AUTOSAR XML (schema 00050)
package /STLASWCs
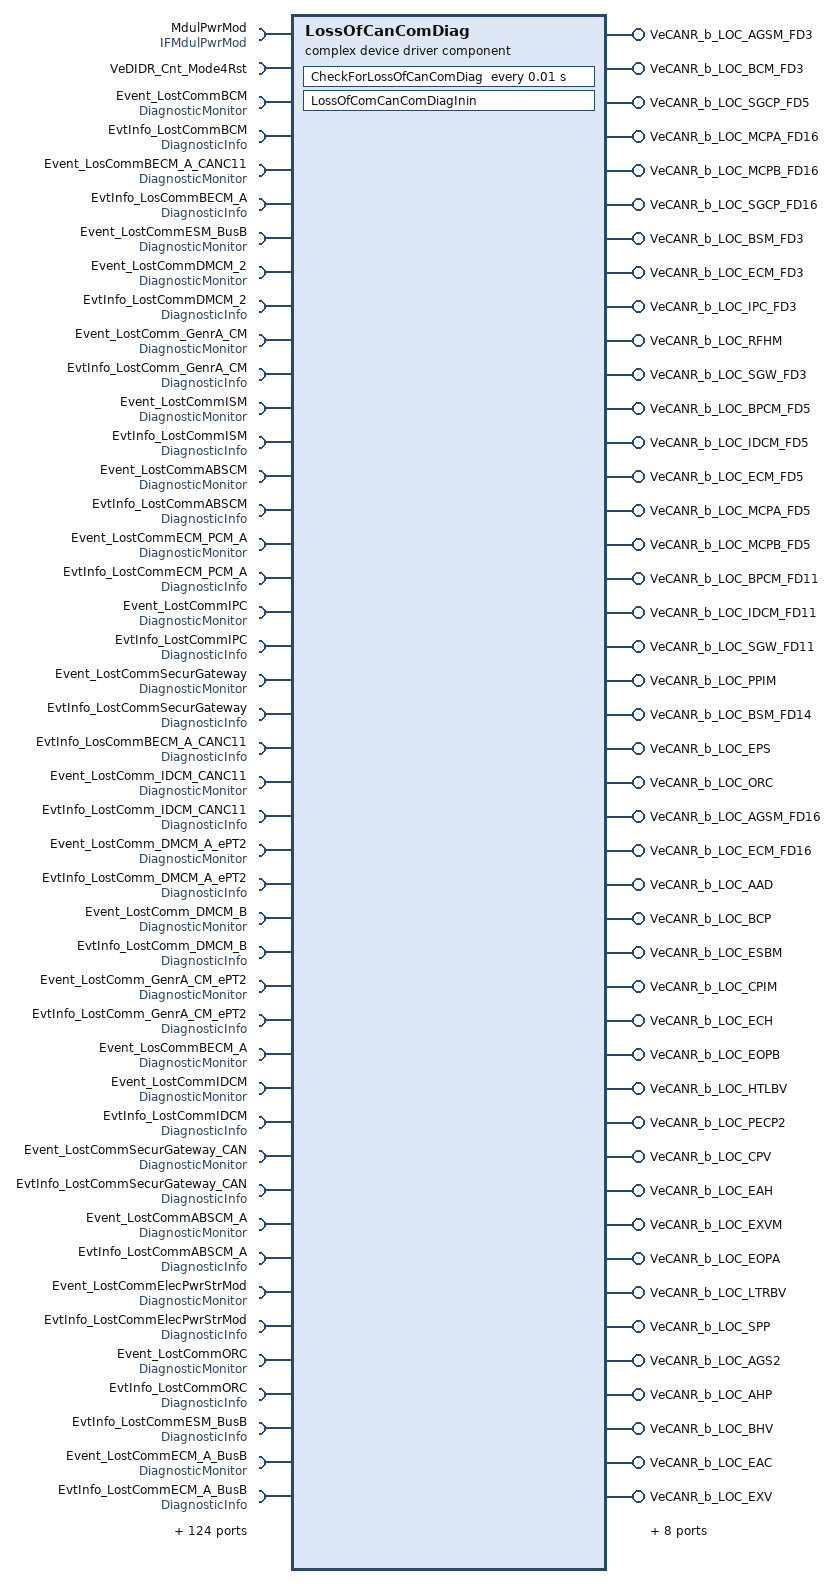
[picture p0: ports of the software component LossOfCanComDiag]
  complex device driver sw component type LossOfCanComDiag  # Loss Of CAN Communication Diagnosis | Loss of CAN Communication Diagnosis Component - implements Loss of Communications (LOC) detection on the CAN bus.
    46 x require port:
      MdulPwrMod: mode-switch-receiver-com-spec=AppMode_MDGP_ESH_Mode, required-interface=IFMdulPwrMod
      VeDIDR_Cnt_Mode4Rst: nonqueued-receiver-com-spec{data-element=VeDIDR_Cnt_Mode4Rst, init-value=0}, required-interface=VeDIDR_Cnt_Mode4Rst
      Event_LostCommBCM: client-com-spec=SetEventStatus, required-interface=DiagnosticMonitor
      EvtInfo_LostCommBCM: client-com-spec=GetEventStatus, required-interface=DiagnosticInfo
      Event_LosCommBECM_A_CANC11: client-com-spec=SetEventStatus, required-interface=DiagnosticMonitor
      EvtInfo_LosCommBECM_A: client-com-spec=GetEventStatus, required-interface=DiagnosticInfo
      Event_LostCommESM_BusB: client-com-spec=SetEventStatus, required-interface=DiagnosticMonitor
      Event_LostCommDMCM_2: client-com-spec=SetEventStatus, required-interface=DiagnosticMonitor
      EvtInfo_LostCommDMCM_2: client-com-spec=GetEventStatus, required-interface=DiagnosticInfo
      Event_LostComm_GenrA_CM: client-com-spec=SetEventStatus, required-interface=DiagnosticMonitor
      EvtInfo_LostComm_GenrA_CM: client-com-spec=GetEventStatus, required-interface=DiagnosticInfo
      Event_LostCommISM: client-com-spec=SetEventStatus, required-interface=DiagnosticMonitor
      EvtInfo_LostCommISM: client-com-spec=GetEventStatus, required-interface=DiagnosticInfo
      Event_LostCommABSCM: client-com-spec=SetEventStatus, required-interface=DiagnosticMonitor
      EvtInfo_LostCommABSCM: client-com-spec=GetEventStatus, required-interface=DiagnosticInfo
      Event_LostCommECM_PCM_A: client-com-spec=SetEventStatus, required-interface=DiagnosticMonitor
      EvtInfo_LostCommECM_PCM_A: client-com-spec=GetEventStatus, required-interface=DiagnosticInfo
      Event_LostCommIPC: client-com-spec=SetEventStatus, required-interface=DiagnosticMonitor
      EvtInfo_LostCommIPC: client-com-spec=GetEventStatus, required-interface=DiagnosticInfo
      Event_LostCommSecurGateway: client-com-spec=SetEventStatus, required-interface=DiagnosticMonitor
      EvtInfo_LostCommSecurGateway: client-com-spec=GetEventStatus, required-interface=DiagnosticInfo
      EvtInfo_LosCommBECM_A_CANC11: client-com-spec=GetEventStatus, required-interface=DiagnosticInfo
      Event_LostComm_IDCM_CANC11: client-com-spec=SetEventStatus, required-interface=DiagnosticMonitor
      EvtInfo_LostComm_IDCM_CANC11: client-com-spec=GetEventStatus, required-interface=DiagnosticInfo
      Event_LostComm_DMCM_A_ePT2: client-com-spec=SetEventStatus, required-interface=DiagnosticMonitor
      EvtInfo_LostComm_DMCM_A_ePT2: client-com-spec=GetEventStatus, required-interface=DiagnosticInfo
      Event_LostComm_DMCM_B: client-com-spec=SetEventStatus, required-interface=DiagnosticMonitor
      EvtInfo_LostComm_DMCM_B: client-com-spec=GetEventStatus, required-interface=DiagnosticInfo
      Event_LostComm_GenrA_CM_ePT2: client-com-spec=SetEventStatus, required-interface=DiagnosticMonitor
      EvtInfo_LostComm_GenrA_CM_ePT2: client-com-spec=GetEventStatus, required-interface=DiagnosticInfo
      Event_LosCommBECM_A: client-com-spec=SetEventStatus, required-interface=DiagnosticMonitor
      Event_LostCommIDCM: client-com-spec=SetEventStatus, required-interface=DiagnosticMonitor
      EvtInfo_LostCommIDCM: client-com-spec=GetEventStatus, required-interface=DiagnosticInfo
      Event_LostCommSecurGateway_CAN: client-com-spec=SetEventStatus, required-interface=DiagnosticMonitor
      EvtInfo_LostCommSecurGateway_CAN: client-com-spec=GetEventStatus, required-interface=DiagnosticInfo
      Event_LostCommABSCM_A: client-com-spec=SetEventStatus, required-interface=DiagnosticMonitor
      EvtInfo_LostCommABSCM_A: client-com-spec=GetEventStatus, required-interface=DiagnosticInfo
      Event_LostCommElecPwrStrMod: client-com-spec=SetEventStatus, required-interface=DiagnosticMonitor
      EvtInfo_LostCommElecPwrStrMod: client-com-spec=GetEventStatus, required-interface=DiagnosticInfo
      Event_LostCommORC: client-com-spec=SetEventStatus, required-interface=DiagnosticMonitor
      EvtInfo_LostCommORC: client-com-spec=GetEventStatus, required-interface=DiagnosticInfo
      EvtInfo_LostCommESM_BusB: client-com-spec=GetEventStatus, required-interface=DiagnosticInfo
      Event_LostCommECM_A_BusB: client-com-spec=SetEventStatus, required-interface=DiagnosticMonitor
      EvtInfo_LostCommECM_A_BusB: client-com-spec=GetEventStatus, required-interface=DiagnosticInfo
      Event_LostComm_DMCM_A: client-com-spec=SetEventStatus, required-interface=DiagnosticMonitor
      EvtInfo_LostComm_DMCM_A: client-com-spec=GetEventStatus, required-interface=DiagnosticInfo
    25 x provide port:
      VeCANR_b_LOC_AGSM_FD3: nonqueued-sender-com-spec{data-element=VeCANR_b_LOC_AGSM_FD3, init-value=0}, provided-interface=VeCANR_b_LOC_AGSM_FD3
      VeCANR_b_LOC_BCM_FD3: nonqueued-sender-com-spec{data-element=VeCANR_b_LOC_BCM_FD3, init-value=0}, provided-interface=VeCANR_b_LOC_BCM_FD3
      VeCANR_b_LOC_SGCP_FD5: nonqueued-sender-com-spec{data-element=VeCANR_b_LOC_SGCP_FD5, init-value=0}, provided-interface=VeCANR_b_LOC_SGCP_FD5
      VeCANR_b_LOC_MCPA_FD16: nonqueued-sender-com-spec{data-element=VeCANR_b_LOC_MCPA_FD16, init-value=0}, provided-interface=VeCANR_b_LOC_MCPA_FD16
      VeCANR_b_LOC_MCPB_FD16: nonqueued-sender-com-spec{data-element=VeCANR_b_LOC_MCPB_FD16, init-value=0}, provided-interface=VeCANR_b_LOC_MCPB_FD16
      VeCANR_b_LOC_SGCP_FD16: nonqueued-sender-com-spec{data-element=VeCANR_b_LOC_SGCP_FD16, init-value=0}, provided-interface=VeCANR_b_LOC_SGCP_FD16
      VeCANR_b_LOC_BSM_FD3: nonqueued-sender-com-spec{data-element=VeCANR_b_LOC_BSM_FD3, init-value=0}, provided-interface=VeCANR_b_LOC_BSM_FD3
      VeCANR_b_LOC_ECM_FD3: nonqueued-sender-com-spec{data-element=VeCANR_b_LOC_ECM_FD3, init-value=0}, provided-interface=VeCANR_b_LOC_ECM_FD3
      VeCANR_b_LOC_IPC_FD3: nonqueued-sender-com-spec{data-element=VeCANR_b_LOC_IPC_FD3, init-value=0}, provided-interface=VeCANR_b_LOC_IPC_FD3
      VeCANR_b_LOC_RFHM: nonqueued-sender-com-spec{data-element=VeCANR_b_LOC_RFHM, init-value=0}, provided-interface=VeCANR_b_LOC_RFHM
      VeCANR_b_LOC_SGW_FD3: nonqueued-sender-com-spec{data-element=VeCANR_b_LOC_SGW_FD3, init-value=0}, provided-interface=VeCANR_b_LOC_SGW_FD3
      VeCANR_b_LOC_BPCM_FD5: nonqueued-sender-com-spec{data-element=VeCANR_b_LOC_BPCM_FD5, init-value=0}, provided-interface=VeCANR_b_LOC_BPCM_FD5
      VeCANR_b_LOC_IDCM_FD5: nonqueued-sender-com-spec{data-element=VeCANR_b_LOC_IDCM_FD5, init-value=0}, provided-interface=VeCANR_b_LOC_IDCM_FD5
      VeCANR_b_LOC_ECM_FD5: nonqueued-sender-com-spec{data-element=VeCANR_b_LOC_ECM_FD5, init-value=0}, provided-interface=VeCANR_b_LOC_ECM_FD5
      VeCANR_b_LOC_MCPA_FD5: nonqueued-sender-com-spec{data-element=VeCANR_b_LOC_MCPA_FD5, init-value=0}, provided-interface=VeCANR_b_LOC_MCPA_FD5
      VeCANR_b_LOC_MCPB_FD5: nonqueued-sender-com-spec{data-element=VeCANR_b_LOC_MCPB_FD5, init-value=0}, provided-interface=VeCANR_b_LOC_MCPB_FD5
      VeCANR_b_LOC_BPCM_FD11: nonqueued-sender-com-spec{data-element=VeCANR_b_LOC_BPCM_FD11, init-value=0}, provided-interface=VeCANR_b_LOC_BPCM_FD11
      VeCANR_b_LOC_IDCM_FD11: nonqueued-sender-com-spec{data-element=VeCANR_b_LOC_IDCM_FD11, init-value=0}, provided-interface=VeCANR_b_LOC_IDCM_FD11
      VeCANR_b_LOC_SGW_FD11: nonqueued-sender-com-spec{data-element=VeCANR_b_LOC_SGW_FD11, init-value=0}, provided-interface=VeCANR_b_LOC_SGW_FD11
      VeCANR_b_LOC_PPIM: nonqueued-sender-com-spec{data-element=VeCANR_b_LOC_PPIM, init-value=0}, provided-interface=VeCANR_b_LOC_PPIM
      VeCANR_b_LOC_BSM_FD14: nonqueued-sender-com-spec{data-element=VeCANR_b_LOC_BSM_FD14, init-value=0}, provided-interface=VeCANR_b_LOC_BSM_FD14
      VeCANR_b_LOC_EPS: nonqueued-sender-com-spec{data-element=VeCANR_b_LOC_EPS, init-value=0}, provided-interface=VeCANR_b_LOC_EPS
      VeCANR_b_LOC_ORC: nonqueued-sender-com-spec{data-element=VeCANR_b_LOC_ORC, init-value=0}, provided-interface=VeCANR_b_LOC_ORC
      VeCANR_b_LOC_AGSM_FD16: nonqueued-sender-com-spec{data-element=VeCANR_b_LOC_AGSM_FD16, init-value=0}, provided-interface=VeCANR_b_LOC_AGSM_FD16
      VeCANR_b_LOC_ECM_FD16: nonqueued-sender-com-spec{data-element=VeCANR_b_LOC_ECM_FD16, init-value=0}, provided-interface=VeCANR_b_LOC_ECM_FD16
    70 x require port:
      VeSR1B_y_BPCM_HV_Current_FD11_SigSts: nonqueued-receiver-com-spec{data-element=Value, init-value=Value:0}, required-interface=VeSR1B_y_BPCM_HV_Current_FD11_SigSts
      VeSR1B_y_IMPACTCommand_FD3_SigSts: nonqueued-receiver-com-spec{data-element=Value, init-value=Value:0}, required-interface=VeSR1B_y_IMPACTCommand_FD3_SigSts
      VeSR1B_y_ShiftLeverPositionReq_FD3_SigSts: nonqueued-receiver-com-spec{data-element=Value, init-value=Value:0}, required-interface=VeSR1B_y_ShiftLeverPositionReq_FD3_SigSts
      VeSR1B_y_MCPA_MaxTorq_P_FD16_SigSts: nonqueued-receiver-com-spec{data-element=Value, init-value=Value:0}, required-interface=VeSR1B_y_MCPA_MaxTorq_P_FD16_SigSts
      VeSR1B_y_MCPB_MaxTorq_P_FD16_SigSts: nonqueued-receiver-com-spec{data-element=Value, init-value=Value:0}, required-interface=VeSR1B_y_MCPB_MaxTorq_P_FD16_SigSts
      VeSR1B_y_SGCP_RPM_P_FD16_SigSts: nonqueued-receiver-com-spec{data-element=Value, init-value=Value:0}, required-interface=VeSR1B_y_SGCP_RPM_P_FD16_SigSts
      VeSR1B_y_EVSE_IsolationSts_FD11_SigSts: nonqueued-receiver-com-spec{data-element=Value, init-value=0}, required-interface=VeSR1B_y_EVSE_IsolationSts_FD11_SigSts
      VeSR1B_y_PRNDFailSts_FD3_SigSts: nonqueued-receiver-com-spec{data-element=Value, init-value=Value:0}, required-interface=VeSR1B_y_PRNDFailSts_FD3_SigSts
      VeSR1B_y_CmdIgnSts_SigSts: nonqueued-receiver-com-spec{data-element=Value, init-value=Value:0}, required-interface=VeSR1B_y_CmdIgnSts_SigSts
      VeSR1B_y_KeyInIgnSts_SigSts: nonqueued-receiver-com-spec{data-element=Value, init-value=Value:0}, required-interface=VeSR1B_y_KeyInIgnSts_SigSts
      VeSR1B_y_BrkTrq_FD3_SigSts: nonqueued-receiver-com-spec{data-element=Value, init-value=Value:0}, required-interface=VeSR1B_y_BrkTrq_FD3_SigSts
      Event_LostCommActAirDamMod: client-com-spec=SetEventStatus, required-interface=DiagnosticMonitor
      EvtInfo_LostCommActAirDamMod: client-com-spec=GetEventStatus, required-interface=DiagnosticInfo
      Event_LostComm_AGS_B: client-com-spec=SetEventStatus, required-interface=DiagnosticMonitor
      EvtInfo_LostCommMtrElectCoolPmpA: client-com-spec=GetEventStatus, required-interface=DiagnosticInfo
      EvtInfo_LostCommCPIM: client-com-spec=GetEventStatus, required-interface=DiagnosticInfo
      Event_LostCommPwrtrn_OilPmp2: client-com-spec=SetEventStatus, required-interface=DiagnosticMonitor
      EvtInfo_LostCommPwrtrn_OilPmp2: client-com-spec=GetEventStatus, required-interface=DiagnosticInfo
      Event_LostCommMtrElectCoolPmpB: client-com-spec=SetEventStatus, required-interface=DiagnosticMonitor
      EvtInfo_LostCommMtrElectCoolPmpB: client-com-spec=GetEventStatus, required-interface=DiagnosticInfo
      Event_LostCommHB_CoolPmp: client-com-spec=SetEventStatus, required-interface=DiagnosticMonitor
      EvtInfo_LostCommHB_CoolPmp: client-com-spec=GetEventStatus, required-interface=DiagnosticInfo
      Event_LosCommHybPSCCtrlValA: client-com-spec=SetEventStatus, required-interface=DiagnosticMonitor
      EvtInfo_LosCommHybPSCCtrlValA: client-com-spec=GetEventStatus, required-interface=DiagnosticInfo
      Event_LostCommCoolHtrA: client-com-spec=SetEventStatus, required-interface=DiagnosticMonitor
      EvtInfo_LostCommCoolHtrA: client-com-spec=GetEventStatus, required-interface=DiagnosticInfo
      Event_LostCommACRefrigExpVlvActA: client-com-spec=SetEventStatus, required-interface=DiagnosticMonitor
      EvtInfo_LostCommACRefrigExpVlvActA: client-com-spec=GetEventStatus, required-interface=DiagnosticInfo
      Event_LostCommPwrtrn_OilPmp1: client-com-spec=SetEventStatus, required-interface=DiagnosticMonitor
      EvtInfo_LostCommPwrtrn_OilPmp1: client-com-spec=GetEventStatus, required-interface=DiagnosticInfo
      EvtInfo_LostComm_AGS_B: client-com-spec=GetEventStatus, required-interface=DiagnosticInfo
      Event_LostCommCoolPmpA: client-com-spec=SetEventStatus, required-interface=DiagnosticMonitor
      EvtInfo_LostCommCoolPmpA: client-com-spec=GetEventStatus, required-interface=DiagnosticInfo
      Event_LostCommBHVDummy: client-com-spec=SetEventStatus, required-interface=DiagnosticMonitor
      Event_LostCommEAC: client-com-spec=SetEventStatus, required-interface=DiagnosticMonitor
      EvtInfo_LostCommEAC: client-com-spec=GetEventStatus, required-interface=DiagnosticInfo
      Event_LostCommACRefrigExpVlvActC: client-com-spec=SetEventStatus, required-interface=DiagnosticMonitor
      EvtInfo_LostCommACRefrigExpVlvActC: client-com-spec=GetEventStatus, required-interface=DiagnosticInfo
      Event_LostCommMtrElectCoolPmpA: client-com-spec=SetEventStatus, required-interface=DiagnosticMonitor
      Event_LostComm_AGS_A: client-com-spec=SetEventStatus, required-interface=DiagnosticMonitor
      EvtInfo_LostComm_AGS_A: client-com-spec=GetEventStatus, required-interface=DiagnosticInfo
      Event_LostCommACRefrigExpVlvActD: client-com-spec=SetEventStatus, required-interface=DiagnosticMonitor
      EvtInfo_LostCommACRefrigExpVlvActD: client-com-spec=GetEventStatus, required-interface=DiagnosticInfo
      Event_LostCommCPIM: client-com-spec=SetEventStatus, required-interface=DiagnosticMonitor
      VeLINR_d_LIN_SlavePrsntSts_LIN{1..3}: nonqueued-receiver-com-spec{data-element=VeLINR_d_LIN_SlavePrsntSts_LIN{1..3}, init-value=Value:0}, required-interface=VeLINR_d_LIN_SlavePrsntSts_LIN{1..3}
      VeLINR_b_EXV_ERR_LIN2TO: nonqueued-receiver-com-spec{data-element=VeLINR_b_OEXV_ERR_TO, init-value=0}, required-interface=VeLINR_b_OEXV_ERR_TO
      VeLINR_b_AAD_CurrPosTO: nonqueued-receiver-com-spec{data-element=VeLINR_b_AAD_CurrPosTO, init-value=0}, required-interface=VeLINR_b_AAD_CurrPosTO
      VeLINR_b_PECP_RPM_ACTL_PERCT_TO: nonqueued-receiver-com-spec{data-element=VeLINR_b_PECP_RPM_ACTL_PERCT_TO, init-value=0}, required-interface=VeLINR_b_PECP_RPM_ACTL_PERCT_TO
      VeLINR_b_PowerPanelButton_StateTO: nonqueued-receiver-com-spec{data-element=VeLINR_b_PowerPanelButton_StateTO, init-value=0}, required-interface=VeLINR_b_PowerPanelButton_StateTO
      VeLINR_b_AGS_CurrPosTO: nonqueued-receiver-com-spec{data-element=VeLINR_b_AGS_CurrPosTO, init-value=0}, required-interface=VeLINR_b_AGS_CurrPosTO
      VeLINR_b_CEXV_PosActTO: nonqueued-receiver-com-spec{data-element=VeLINR_b_CEXV_PosActTO, init-value=0}, required-interface=VeLINR_b_CEXV_PosActTO
      VeLINR_b_Ambient_TempTO: nonqueued-receiver-com-spec{data-element=VeLINR_b_Ambient_TempTO, init-value=0}, required-interface=VeLINR_b_Ambient_TempTO
      VeLINR_b_BCP_RPM_ACTUAL_TO: nonqueued-receiver-com-spec{data-element=VeLINR_b_BCP_RPM_ACTUAL_TO, init-value=0}, required-interface=VeLINR_b_BCP_RPM_ACTUAL_TO
      VeLINR_b_CPV_CalStatTO: nonqueued-receiver-com-spec{data-element=VeLINR_b_CPV_CalStatTO, init-value=0}, required-interface=VeLINR_b_CPV_CalStatTO
      VeLINR_b_AirHeatrPwrCnsTO: nonqueued-receiver-com-spec{data-element=VeLINR_b_AirHeatrPwrCnsTO, init-value=0}, required-interface=VeLINR_b_AirHeatrPwrCnsTO
      VeLINR_b_EXV_ERR_LIN1TO: nonqueued-receiver-com-spec{data-element=VeLINR_b_EEXV_ERR_TO, init-value=0}, required-interface=VeLINR_b_EEXV_ERR_TO
      VeLINR_b_EOPA_CURR_TO: nonqueued-receiver-com-spec{data-element=VeLINR_b_EOPA_CURR_TO, init-value=0}, required-interface=VeLINR_b_EOPA_CURR_TO
      VeLINR_b_AGS2_CurrPosTO: nonqueued-receiver-com-spec{data-element=VeLINR_b_AGS2_CurrPosTO, init-value=0}, required-interface=VeLINR_b_AGS2_CurrPosTO
      VeLINR_b_AHP_RPM_ACTL_PERCT_TO: nonqueued-receiver-com-spec{data-element=VeLINR_b_AHP_RPM_ACTL_PERCT_TO, init-value=0}, required-interface=VeLINR_b_AHP_RPM_ACTL_PERCT_TO
      VeLINR_b_BHV_CalStatTO: nonqueued-receiver-com-spec{data-element=VeLINR_b_BHV_CalStatTO, init-value=0}, required-interface=VeLINR_b_BHV_CalStatTO
      VeLINR_b_CompFaultStatTO: nonqueued-receiver-com-spec{data-element=VeLINR_b_CompFaultStatTO, init-value=0}, required-interface=VeLINR_b_CompFaultStatTO
      VeLINR_b_DriveMdReqTO: nonqueued-receiver-com-spec{data-element=VeLINR_b_DriveMdReqTO, init-value=0}, required-interface=VeLINR_b_DriveMdReqTO
      VeLINR_b_Inlet_Temp1_DC_TO: nonqueued-receiver-com-spec{data-element=VeLINR_b_Inlet_Temp1_DC_TO, init-value=0}, required-interface=VeLINR_b_Inlet_Temp1_DC_TO
      VeLINR_b_HvCooltHeatrICnsTO: nonqueued-receiver-com-spec{data-element=VeLINR_b_HvCooltHeatrICnsTO, init-value=0}, required-interface=VeLINR_b_HvCooltHeatrICnsTO
      VeLINR_b_EOPB_CURR_TO: nonqueued-receiver-com-spec{data-element=VeLINR_b_EOPB_CURR_TO, init-value=0}, required-interface=VeLINR_b_EOPB_CURR_TO
      VeLINR_b_EOPB_OIL_TEMP_TO: nonqueued-receiver-com-spec{data-element=VeLINR_b_EOPB_OIL_TEMP_TO, init-value=0}, required-interface=VeLINR_b_EOPB_OIL_TEMP_TO
      VeLINR_b_PECP2_CURR_TO: nonqueued-receiver-com-spec{data-element=VeLINR_b_PECP2_CURR_TO, init-value=0}, required-interface=VeLINR_b_PECP2_CURR_TO
      VeLINR_b_PowerPanel2ButtonStateTO: nonqueued-receiver-com-spec{data-element=VeLINR_b_PowerPanel2ButtonStateTO, init-value=0}, required-interface=VeLINR_b_PowerPanel2ButtonStateTO
    23 x provide port:
      VeCANR_b_LOC_AAD: nonqueued-sender-com-spec{data-element=VeCANR_b_LOC_AAD, init-value=0}, provided-interface=VeCANR_b_LOC_AAD
      VeCANR_b_LOC_BCP: nonqueued-sender-com-spec{data-element=VeCANR_b_LOC_BCP, init-value=0}, provided-interface=VeCANR_b_LOC_BCP
      VeCANR_b_LOC_ESBM: nonqueued-sender-com-spec{data-element=VeCANR_b_LOC_ESBM, init-value=0}, provided-interface=VeCANR_b_LOC_ESBM
      VeCANR_b_LOC_CPIM: nonqueued-sender-com-spec{data-element=VeCANR_b_LOC_CPIM, init-value=0}, provided-interface=VeCANR_b_LOC_CPIM
      VeCANR_b_LOC_ECH: nonqueued-sender-com-spec{data-element=VeCANR_b_LOC_ECH, init-value=0}, provided-interface=VeCANR_b_LOC_ECH
      VeCANR_b_LOC_EOPB: nonqueued-sender-com-spec{data-element=VeCANR_b_LOC_EOPB, init-value=0}, provided-interface=VeCANR_b_LOC_EOPB
      VeCANR_b_LOC_HTLBV: nonqueued-sender-com-spec{data-element=VeCANR_b_LOC_HTLBV, init-value=0}, provided-interface=VeCANR_b_LOC_HTLBV
      VeCANR_b_LOC_PECP2: nonqueued-sender-com-spec{data-element=VeCANR_b_LOC_PECP2, init-value=0}, provided-interface=VeCANR_b_LOC_PECP2
      VeCANR_b_LOC_CPV: nonqueued-sender-com-spec{data-element=VeCANR_b_LOC_CPV, init-value=0}, provided-interface=VeCANR_b_LOC_CPV
      VeCANR_b_LOC_EAH: nonqueued-sender-com-spec{data-element=VeCANR_b_LOC_EAH, init-value=0}, provided-interface=VeCANR_b_LOC_EAH
      VeCANR_b_LOC_EXVM: nonqueued-sender-com-spec{data-element=VeCANR_b_LOC_EXVM, init-value=0}, provided-interface=VeCANR_b_LOC_EXVM
      VeCANR_b_LOC_EOPA: nonqueued-sender-com-spec{data-element=VeCANR_b_LOC_EOPA, init-value=0}, provided-interface=VeCANR_b_LOC_EOPA
      VeCANR_b_LOC_LTRBV: nonqueued-sender-com-spec{data-element=VeCANR_b_LOC_LTRBV, init-value=0}, provided-interface=VeCANR_b_LOC_LTRBV
      VeCANR_b_LOC_SPP: nonqueued-sender-com-spec{data-element=VeCANR_b_LOC_SPP, init-value=0}, provided-interface=VeCANR_b_LOC_SPP
      VeCANR_b_LOC_AGS2: nonqueued-sender-com-spec{data-element=VeCANR_b_LOC_AGS2, init-value=0}, provided-interface=VeCANR_b_LOC_AGS2
      VeCANR_b_LOC_AHP: nonqueued-sender-com-spec{data-element=VeCANR_b_LOC_AHP, init-value=0}, provided-interface=VeCANR_b_LOC_AHP
      VeCANR_b_LOC_BHV: nonqueued-sender-com-spec{data-element=VeCANR_b_LOC_BHV, init-value=0}, provided-interface=VeCANR_b_LOC_BHV
      VeCANR_b_LOC_EAC: nonqueued-sender-com-spec{data-element=VeCANR_b_LOC_EAC, init-value=0}, provided-interface=VeCANR_b_LOC_EAC
      VeCANR_b_LOC_EXV: nonqueued-sender-com-spec{data-element=VeCANR_b_LOC_EXV, init-value=0}, provided-interface=VeCANR_b_LOC_EXV
      VeCANR_b_LOC_PECP: nonqueued-sender-com-spec{data-element=VeCANR_b_LOC_PECP, init-value=0}, provided-interface=VeCANR_b_LOC_PECP
      VeCANR_b_LOC_SPP2: nonqueued-sender-com-spec{data-element=VeCANR_b_LOC_SPP2, init-value=0}, provided-interface=VeCANR_b_LOC_SPP2
      VeCANR_b_LOC_AGS: nonqueued-sender-com-spec{data-element=VeCANR_b_LOC_AGS, init-value=0}, provided-interface=VeCANR_b_LOC_AGS
      VeCANR_b_LOC_CEXV: nonqueued-sender-com-spec{data-element=VeCANR_b_LOC_CEXV, init-value=0}, provided-interface=VeCANR_b_LOC_CEXV
    9 x require port:
      KeCFGR_b_LIN{1..3}_Equid: parameter-require-com-spec{init-value=Value:1, parameter=KeCFGR_b_LIN{1..3}_Equid}, required-interface=KeCFGR_b_LIN{1..3}_Equid
      VeSR1B_y_FOTA_Install_Type_SigSts: nonqueued-receiver-com-spec{data-element=Value, init-value=Value:0}, required-interface=VeSR1B_y_FOTA_Install_Type_SigSts
      VeSR1B_y_ShiftLeverPositionReq_SigSts: nonqueued-receiver-com-spec{data-element=Value, init-value=Value:0}, required-interface=VeSR1B_y_ShiftLeverPositionReq_SigSts
      VeSR1B_y_MCPA_DTC_Idx1_FD16_SigSts: nonqueued-receiver-com-spec{data-element=Value, init-value=0}, required-interface=VeSR1B_y_MCPA_DTC_Idx1_FD16_SigSts
      VeSR1B_y_EngineSpeed_W_FD16_SigSts: nonqueued-receiver-com-spec{data-element=Value, init-value=Value:0}, required-interface=VeSR1B_y_EngineSpeed_W_FD16_SigSts
      VeSR1B_y_MCPB_DTC_Idx1_FD16_SigSts: nonqueued-receiver-com-spec{data-element=Value, init-value=0}, required-interface=VeSR1B_y_MCPB_DTC_Idx1_FD16_SigSts
      VeSR1B_y_SGCP_DTC_Idx1_FD16_SigSts: nonqueued-receiver-com-spec{data-element=Value, init-value=0}, required-interface=VeSR1B_y_SGCP_DTC_Idx1_FD16_SigSts
    provide port VeCANR_e_CanLocEnblStatus: nonqueued-sender-com-spec{data-element=VeCANR_e_CanLocEnblStatus, init-value=Value:0}, provided-interface=VeCANR_e_CanLocEnblStatus
    25 x require port:
      Pp_DcmControlDTCSetting: mode-switch-receiver-com-spec=MDGP_DcmControlDTCSetting, required-interface=DcmControlDTCSetting
      VeBATR_U_12VoltSys: required-interface=VeBATR_U_12VoltSys
      GetDMRR_g_EnblCondSts: client-com-spec=GetDMRR_g_EnblCondSts, required-interface=GetDMRR_g_EnblCondSts
      VeCANR_b_CurrBusOpenSt_FD3: nonqueued-receiver-com-spec{data-element=VeCANR_b_CurrBusOpenSt_FD3, init-value=0}, required-interface=VeCANR_b_CurrBusOpenSt_FD3
      KeCFGR_b_FD14_equid: parameter-require-com-spec{init-value=Value:1, parameter=KeCFGR_b_FD14_equid}, required-interface=KeCFGR_b_FD14_equid
      KeCFGR_b_FD11_equid: parameter-require-com-spec{init-value=Value:1, parameter=KeCFGR_b_FD11_equid}, required-interface=KeCFGR_b_FD11_equid
      KeCFGR_b_FD3_equid: parameter-require-com-spec{init-value=Value:1, parameter=KeCFGR_b_FD3_equid}, required-interface=KeCFGR_b_FD3_equid
      KeCFGR_b_FD5_equid: parameter-require-com-spec{init-value=Value:1, parameter=KeCFGR_b_FD5_equid}, required-interface=KeCFGR_b_FD5_equid
      KeCFGR_b_FD16_equid: parameter-require-com-spec{init-value=Value:1, parameter=KeCFGR_b_FD16_equid}, required-interface=KeCFGR_b_FD16_equid
      VeSR1B_y_CmdTotBrkFricAxTrqFD14_SigSts: nonqueued-receiver-com-spec{data-element=Value, init-value=Value:0}, required-interface=VeSR1B_y_CmdTotBrkFricAxTrqFD14_SigSts
      VeCANR_b_CurrBusOpenSt_FD5: nonqueued-receiver-com-spec{data-element=VeCANR_b_CurrBusOpenSt_FD5, init-value=0}, required-interface=VeCANR_b_CurrBusOpenSt_FD5
      VeCANR_b_CurrBusOpenSt_FD16: nonqueued-receiver-com-spec{data-element=VeCANR_b_CurrBusOpenSt_FD16, init-value=0}, required-interface=VeCANR_b_CurrBusOpenSt_FD16
      VeCANR_b_CurrBusOpenSt_FD14: nonqueued-receiver-com-spec{data-element=VeCANR_b_CurrBusOpenSt_FD14, init-value=0}, required-interface=VeCANR_b_CurrBusOpenSt_FD14
      VeCANR_b_CurrBusOpenSt_FD11: nonqueued-receiver-com-spec{data-element=VeCANR_b_CurrBusOpenSt_FD11, init-value=0}, required-interface=VeCANR_b_CurrBusOpenSt_FD11
      VeCANR_b_CurrBusOffSt_FD5: nonqueued-receiver-com-spec{data-element=VeCANR_b_CurrBusOffSt_FD5, init-value=0}, required-interface=VeCANR_b_CurrBusOffSt_FD5
      VeCANR_b_CurrBusOffSt_FD16: nonqueued-receiver-com-spec{data-element=VeCANR_b_CurrBusOffSt_FD16, init-value=0}, required-interface=VeCANR_b_CurrBusOffSt_FD16
      VeCANR_b_CurrBusOffSt_FD14: nonqueued-receiver-com-spec{data-element=VeCANR_b_CurrBusOffSt_FD14, init-value=0}, required-interface=VeCANR_b_CurrBusOffSt_FD14
      VeCANR_b_CurrBusOffSt_FD11: nonqueued-receiver-com-spec{data-element=VeCANR_b_CurrBusOffSt_FD11, init-value=0}, required-interface=VeCANR_b_CurrBusOffSt_FD11
      VeCANR_b_CurrBusOffSt_FD3: nonqueued-receiver-com-spec{data-element=VeCANR_b_CurrBusOffSt_FD3, init-value=0}, required-interface=VeCANR_b_CurrBusOffSt_FD3
      VeSR1B_y_EngineSpeed_W_FD3_SigSts: nonqueued-receiver-com-spec{data-element=Value, init-value=Value:0}, required-interface=VeSR1B_y_EngineSpeed_W_FD3_SigSts
      VeSR1B_y_TotalOdometer_SigSts: nonqueued-receiver-com-spec{data-element=Value, init-value=Value:0}, required-interface=VeSR1B_y_TotalOdometer_SigSts
      VeSR1B_y_CmdIgnSts: nonqueued-receiver-com-spec{data-element=Value, init-value=Value:0}, required-interface=VeSR1B_y_CmdIgnSts
      VeHPMR_b_CntrlrPwrHold: nonqueued-receiver-com-spec{data-element=Value, init-value=Value:0}, required-interface=VeHPMR_b_CntrlrPwrHold
      EvtInfo_LostCommCVPAMod: client-com-spec=GetEventStatus, required-interface=DiagnosticInfo
      Event_LostCommCVPAMod: client-com-spec=SetEventStatus, required-interface=DiagnosticMonitor
    provide port VeCANR_b_LOC_CADM_FD14: nonqueued-sender-com-spec{data-element=VeCANR_b_LOC_CADM_FD14, init-value=0}, provided-interface=VeCANR_b_LOC_CADM_FD14
    7 x require port:
      VeSR1B_y_MRM_STATUS_FD14_SigSts: nonqueued-receiver-com-spec{data-element=Value, init-value=Value:0}, required-interface=VeSR1B_y_MRM_STATUS_FD14_SigSts
      Event_LostCommBECM_ePT2: client-com-spec=SetEventStatus, required-interface=DiagnosticMonitor
      EvtInfo_LostCommBECM_ePT2: client-com-spec=GetEventStatus, required-interface=DiagnosticInfo
      Event_LostCommRadio: client-com-spec=SetEventStatus, required-interface=DiagnosticMonitor
      EvtInfo_LostCommRadio: client-com-spec=GetEventStatus, required-interface=DiagnosticInfo
      Event_LostCommDCDC: client-com-spec=SetEventStatus, required-interface=DiagnosticMonitor
      EvtInfo_LostCommDCDC: client-com-spec=GetEventStatus, required-interface=DiagnosticInfo
    provide port VeCANR_b_LOC_APM_FD14: nonqueued-sender-com-spec=VeCANR_b_LOC_APM_FD14, provided-interface=VeCANR_b_LOC_APM_FD14
    provide port VeCANR_b_LOC_RFHM_FD3: nonqueued-sender-com-spec=VeCANR_b_LOC_RFHM_FD3, provided-interface=VeCANR_b_LOC_RFHM_FD3
    15 x require port:
      Event_LostComm_DMCM_A_CANC11: client-com-spec=SetEventStatus, required-interface=DiagnosticMonitor
      EvtInfo_LostComm_DMCM_A_CANC11: client-com-spec=GetEventStatus, required-interface=DiagnosticInfo
      Event_LostCommDMCM_2_CANC11: client-com-spec=SetEventStatus, required-interface=DiagnosticMonitor
      EvtInfo_LostCommDMCM_2_CANC11: client-com-spec=GetEventStatus, required-interface=DiagnosticInfo
      Event_LostComm_GenrA_CM_ePT_R: client-com-spec=SetEventStatus, required-interface=DiagnosticMonitor
      EvtInfo_LostComm_GenrA_CM_ePT_R: client-com-spec=GetEventStatus, required-interface=DiagnosticInfo
      Event_LostCommECM: client-com-spec=SetEventStatus, required-interface=DiagnosticMonitor
      EvtInfo_LostCommECM: client-com-spec=GetEventStatus, required-interface=DiagnosticInfo
      Event_LostCommRHSC2: client-com-spec=SetEventStatus, required-interface=DiagnosticMonitor
      EvtInfo_LostCommRHSC2: client-com-spec=GetEventStatus, required-interface=DiagnosticInfo
      VeSR1B_y_EngMnSprkNmCrArTqCpFD5_SigSts: nonqueued-receiver-com-spec{data-element=Value, init-value=NumericalValueSpecification_0:0}, required-interface=VeSR1B_y_EngMnSprkNmCrArTqCpFD5_SigSts
      VeSR1B_y_MCPA_MaxTorq_P_FD5_SigSts: nonqueued-receiver-com-spec{data-element=Value, init-value=NumericalValueSpecification_0:0}, required-interface=VeSR1B_y_MCPA_MaxTorq_P_FD5_SigSts
      VeSR1B_y_MCPB_MaxTorq_P_FD5_SigSts: nonqueued-receiver-com-spec{data-element=Value, init-value=NumericalValueSpecification_0:0}, required-interface=VeSR1B_y_MCPB_MaxTorq_P_FD5_SigSts
      VeSR1B_y_SGCP_RPM_P_FD5_SigSts: nonqueued-receiver-com-spec{data-element=Value, init-value=NumericalValueSpecification_0:0}, required-interface=VeSR1B_y_SGCP_RPM_P_FD5_SigSts
      VeSR1B_y_DriverEngineOffRequest_SigSts: nonqueued-receiver-com-spec{data-element=Value, init-value=NumericalValueSpecification_0:0}, required-interface=VeSR1B_y_DriverEngineOffRequest_SigSts
    behavior IBLossOfCanComDiag: data-type-mapping=[BswMMappingSet, ADTtoIDTMapping, DTS_DcmDiagnosticSessionControl, DTS_DcmEcuReset, DTS_DcmControlDTCSetting, DTS_DcmCommunicationControl_Can_Network_CANFD_3], handle-termination-and-restart=NO-SUPPORT
      init event IELossOfCanComDiag: start-on-event=LossOfComCanComDiagInin
      timing event MedTEA1: start-on-event=CheckForLossOfCanComDiag, period=0.01
        disabled-mode:
          MdulPwrMod.AppMode_MDGP_ESH_Mode.STARTUP
          MdulPwrMod.AppMode_MDGP_ESH_Mode.WAKEUP
          MdulPwrMod.AppMode_MDGP_ESH_Mode.SHUTDOWN
      explicit-inter-runnable-variables:
        6 x data, all with init-value=Value:0:
          VeCAND_Cnt_PrevMode4RstComDiag: type=uint8  # Static variable to hold previous value of VeDIDR_Cnt_Mode4Rst
          VeCANR_d_LOC_GlbInhb: category=VALUE, sw-calibration-access=READ-ONLY, type=uint16  # Loss Of Communication Global DiagnosticInhibits | Loss of communication diagnostic inhibits. Each bit is an individual inhibit flag. 1 = inhibited, 0 = not inhibited.
          VeCANR_g_LOC_Sts: category=VALUE, sw-calibration-access=READ-ONLY, type=uint32  # Loss Of Communication Status | Loss of communication status for all monitored modules. Each bit represents a module: 1=loss of com, 0=not loss of com
          VeCANR_t_LOC_EnblCondsMetTmr: type=uint16  # Timer for the enable conditions met of loss of com diagnostic
          VeCANR_t_LOC_IniInhbTmr: category=VALUE, sw-calibration-access=READ-ONLY, type=uint16  # Loss Of Communication Diagnostic Initial Inhibit Timer | Timer for the initial time inhibit of loss of com diagnostic
          VeLRNR_d_LIN_LOC_SlaveSts: type=uint16
      runnable CheckForLossOfCanComDiag: symbol=LossOfCanComDiag_CheckForLossOfCanComDiag  # Check For Loss Of CAN Communication Diagnosis
        data-receive-point-by-arguments:
          64 x access:
            DRP_VeDIDR_Cnt_Mode4Rst_VeDIDR_Cnt_Mode4Rst: accessed-variable=VeDIDR_Cnt_Mode4Rst.VeDIDR_Cnt_Mode4Rst
            DRP_SR1B_y_EVSE_IsolationSts_Value: accessed-variable=VeSR1B_y_EVSE_IsolationSts_FD11_SigSts.Value
            DRP_VeLINR_b_AAD_CurrPosTO_VeLINR_b_AAD_CurrPosTO: accessed-variable=VeLINR_b_AAD_CurrPosTO.VeLINR_b_AAD_CurrPosTO
            DRP_VeLINR_b_AGS2_CurrPosTO_VeLINR_b_AGS2_CurrPosTO: accessed-variable=VeLINR_b_AGS2_CurrPosTO.VeLINR_b_AGS2_CurrPosTO
            DRP_VeLINR_b_AGS_CurrPosTO_VeLINR_b_AGS_CurrPosTO: accessed-variable=VeLINR_b_AGS_CurrPosTO.VeLINR_b_AGS_CurrPosTO
            DRP_VeLINR_b_AHP_RPM_ACTL_PERCT_TO_VeLINR_b_AHP_RPM_ACTL_PERCT_TO: accessed-variable=VeLINR_b_AHP_RPM_ACTL_PERCT_TO.VeLINR_b_AHP_RPM_ACTL_PERCT_TO
            DRP_VeLINR_b_AirHeatrPwrCnsTO_VeLINR_b_AirHeatrPwrCnsTO: accessed-variable=VeLINR_b_AirHeatrPwrCnsTO.VeLINR_b_AirHeatrPwrCnsTO
            DRP_VeLINR_b_Ambient_TempTO_VeLINR_b_Ambient_TempTO: accessed-variable=VeLINR_b_Ambient_TempTO.VeLINR_b_Ambient_TempTO
            DRP_VeLINR_b_BCP_RPM_ACTUAL_TO_VeLINR_b_BCP_RPM_ACTUAL_TO: accessed-variable=VeLINR_b_BCP_RPM_ACTUAL_TO.VeLINR_b_BCP_RPM_ACTUAL_TO
            DRP_VeLINR_b_BHV_CalStatTO_VeLINR_b_BHV_CalStatTO: accessed-variable=VeLINR_b_BHV_CalStatTO.VeLINR_b_BHV_CalStatTO
            DRP_VeLINR_b_CEXV_PosActTO_VeLINR_b_CEXV_PosActTO: accessed-variable=VeLINR_b_CEXV_PosActTO.VeLINR_b_CEXV_PosActTO
            DRP_VeLINR_b_CPV_CalStatTO_VeLINR_b_CPV_CalStatTO: accessed-variable=VeLINR_b_CPV_CalStatTO.VeLINR_b_CPV_CalStatTO
            DRP_VeLINR_b_CompFaultStatTO_VeLINR_b_CompFaultStatTO: accessed-variable=VeLINR_b_CompFaultStatTO.VeLINR_b_CompFaultStatTO
            DRP_VeLINR_b_DriveMdReqTO_VeLINR_b_DriveMdReqTO: accessed-variable=VeLINR_b_DriveMdReqTO.VeLINR_b_DriveMdReqTO
            DRP_VeLINR_b_EOPA_CURR_TO_VeLINR_b_EOPA_CURR_TO: accessed-variable=VeLINR_b_EOPA_CURR_TO.VeLINR_b_EOPA_CURR_TO
            DRP_VeLINR_b_EOPB_CURR_TO_VeLINR_b_EOPB_CURR_TO: accessed-variable=VeLINR_b_EOPB_CURR_TO.VeLINR_b_EOPB_CURR_TO
            DRP_VeLINR_b_EOPB_OIL_TEMP_TO_VeLINR_b_EOPB_OIL_TEMP_TO: accessed-variable=VeLINR_b_EOPB_OIL_TEMP_TO.VeLINR_b_EOPB_OIL_TEMP_TO
            DRP_VeLINR_b_EXV_ERR_LIN1TO_VeLINR_b_EXV_ERR_LIN1TO: accessed-variable=VeLINR_b_EXV_ERR_LIN1TO.VeLINR_b_EEXV_ERR_TO
            DRP_VeLINR_b_EXV_ERR_LIN2TO_VeLINR_b_EXV_ERR_LIN2TO: accessed-variable=VeLINR_b_EXV_ERR_LIN2TO.VeLINR_b_OEXV_ERR_TO
            DRP_VeLINR_b_HvCooltHeatrICnsTO_VeLINR_b_HvCooltHeatrICnsTO: accessed-variable=VeLINR_b_HvCooltHeatrICnsTO.VeLINR_b_HvCooltHeatrICnsTO
            DRP_VeLINR_b_Inlet_Temp1_DC_TO_VeLINR_b_Inlet_Temp1_DC_TO: accessed-variable=VeLINR_b_Inlet_Temp1_DC_TO.VeLINR_b_Inlet_Temp1_DC_TO
            DRP_VeLINR_b_PECP2_CURR_TO_VeLINR_b_PECP2_CURR_TO: accessed-variable=VeLINR_b_PECP2_CURR_TO.VeLINR_b_PECP2_CURR_TO
            DRP_VeLINR_b_PECP_RPM_ACTL_PERCT_TO_VeLINR_b_PECP_RPM_ACTL_PERCT_TO: accessed-variable=VeLINR_b_PECP_RPM_ACTL_PERCT_TO.VeLINR_b_PECP_RPM_ACTL_PERCT_TO
            DRP_VeLINR_b_PowerPanel2ButtonStateTO_VeLINR_b_PowerPanel2ButtonStateTO: accessed-variable=VeLINR_b_PowerPanel2ButtonStateTO.VeLINR_b_PowerPanel2ButtonStateTO
            DRP_VeLINR_b_PowerPanelButton_StateTO_VeLINR_b_PowerPanelButton_StateTO: accessed-variable=VeLINR_b_PowerPanelButton_StateTO.VeLINR_b_PowerPanelButton_StateTO
            DRP_VeLINR_d_LIN_SlavePrsntSts_LIN{1..3}_VeLINR_d_LIN_SlavePrsntSts_LIN{1..3}: accessed-variable=VeLINR_d_LIN_SlavePrsntSts_LIN{1..3}.VeLINR_d_LIN_SlavePrsntSts_LIN{1..3}
            DRP_VeSR1B_y_BPCM_HV_Current_FD11_SigSts_Value: accessed-variable=VeSR1B_y_BPCM_HV_Current_FD11_SigSts.Value
            DRP_VeSR1B_y_MRM_STATUS_FD14_SigSts_Value: accessed-variable=VeSR1B_y_MRM_STATUS_FD14_SigSts.Value
            DRP_VeSR1B_y_BrkTrq_FD3_SigSts_Value: accessed-variable=VeSR1B_y_BrkTrq_FD3_SigSts.Value
            DRP_VeSR1B_y_CmdIgnSts_SigSts_Value: accessed-variable=VeSR1B_y_CmdIgnSts_SigSts.Value
            DRP_VeSR1B_y_IMPACTCommand_FD3_SigSts_Value: accessed-variable=VeSR1B_y_IMPACTCommand_FD3_SigSts.Value
            DRP_VeSR1B_y_KeyInIgnSts_SigSts_Value: accessed-variable=VeSR1B_y_KeyInIgnSts_SigSts.Value
            DRP_VeSR1B_y_PRNDFailSts_FD3_SigSts_Value: accessed-variable=VeSR1B_y_PRNDFailSts_FD3_SigSts.Value
            DRP_VeSR1B_y_ShiftLeverPositionReq_FD3_SigSts_Value: accessed-variable=VeSR1B_y_ShiftLeverPositionReq_FD3_SigSts.Value
            DRP_VeSR1B_y_EngineSpeed_W_FD16_SigSts_Value: accessed-variable=VeSR1B_y_EngineSpeed_W_FD16_SigSts.Value
            DRP_VeSR1B_y_FOTA_Install_Type_SigSts_Value: accessed-variable=VeSR1B_y_FOTA_Install_Type_SigSts.Value
            DRP_VeSR1B_y_ShiftLeverPositionReq_SigSts_Value: accessed-variable=VeSR1B_y_ShiftLeverPositionReq_SigSts.Value
            DRP_VeBATR_U_12VoltSys_VeBATR_U_12VoltSys: accessed-variable=VeBATR_U_12VoltSys.VeBATR_U_12VoltSys
            DRP_VeCANR_b_CurrBusOpenSt_FD3_VeCANR_b_CurrBusOpenSt_FD3: accessed-variable=VeCANR_b_CurrBusOpenSt_FD3.VeCANR_b_CurrBusOpenSt_FD3
            DRP_VeCANR_b_CurrBusOffSt_FD11_VeCANR_b_CurrBusOffSt_FD11: accessed-variable=VeCANR_b_CurrBusOffSt_FD11.VeCANR_b_CurrBusOffSt_FD11
            DRP_VeCANR_b_CurrBusOffSt_FD14_VeCANR_b_CurrBusOffSt_FD14: accessed-variable=VeCANR_b_CurrBusOffSt_FD14.VeCANR_b_CurrBusOffSt_FD14
            DRP_VeCANR_b_CurrBusOffSt_FD16_VeCANR_b_CurrBusOffSt_FD16: accessed-variable=VeCANR_b_CurrBusOffSt_FD16.VeCANR_b_CurrBusOffSt_FD16
            DRP_VeCANR_b_CurrBusOffSt_FD5_VeCANR_b_CurrBusOffSt_FD5: accessed-variable=VeCANR_b_CurrBusOffSt_FD5.VeCANR_b_CurrBusOffSt_FD5
            DRP_VeCANR_b_CurrBusOpenSt_FD11_VeCANR_b_CurrBusOpenSt_FD11: accessed-variable=VeCANR_b_CurrBusOpenSt_FD11.VeCANR_b_CurrBusOpenSt_FD11
            DRP_VeCANR_b_CurrBusOpenSt_FD14_VeCANR_b_CurrBusOpenSt_FD14: accessed-variable=VeCANR_b_CurrBusOpenSt_FD14.VeCANR_b_CurrBusOpenSt_FD14
            DRP_VeCANR_b_CurrBusOpenSt_FD5_VeCANR_b_CurrBusOpenSt_FD5: accessed-variable=VeCANR_b_CurrBusOpenSt_FD5.VeCANR_b_CurrBusOpenSt_FD5
            DRP_VeCANR_b_CurrBusOpenSt_FD16_VeCANR_b_CurrBusOpenSt_FD16: accessed-variable=VeCANR_b_CurrBusOpenSt_FD16.VeCANR_b_CurrBusOpenSt_FD16
            DRP_VeCANR_b_CurrBusOffSt_FD3_VeCANR_b_CurrBusOffSt_FD3: accessed-variable=VeCANR_b_CurrBusOffSt_FD3.VeCANR_b_CurrBusOffSt_FD3
            DRP_VeSR1B_y_CmdTotBrkFricAxTrqFD14_SigSts_Value: accessed-variable=VeSR1B_y_CmdTotBrkFricAxTrqFD14_SigSts.Value
            DRP_VeSR1B_y_TotalOdometer_SigSts_Value: accessed-variable=VeSR1B_y_TotalOdometer_SigSts.Value
            DRP_VeSR1B_y_SGCP_RPM_P_FD16_SigSts_Value: accessed-variable=VeSR1B_y_SGCP_RPM_P_FD16_SigSts.Value
            DRP_VeSR1B_y_MCPB_MaxTorq_P_FD16_SigSts_Value: accessed-variable=VeSR1B_y_MCPB_MaxTorq_P_FD16_SigSts.Value
            DRP_VeSR1B_y_MCPA_MaxTorq_P_FD16_SigSts_Value: accessed-variable=VeSR1B_y_MCPA_MaxTorq_P_FD16_SigSts.Value
            DRP_VeSR1B_y_CmdIgnSts_Value: accessed-variable=VeSR1B_y_CmdIgnSts.Value
            DRP_VeHPMR_b_CntrlrPwrHold_Value: accessed-variable=VeHPMR_b_CntrlrPwrHold.Value
            DRP_VeSR1B_y_MCPA_MaxTorq_P_FD5_SigSts: accessed-variable=VeSR1B_y_MCPA_MaxTorq_P_FD5_SigSts.Value
            DRP_VeSR1B_y_EngineSpeed_W_FD3_SigSts_Value: accessed-variable=VeSR1B_y_EngineSpeed_W_FD3_SigSts.Value
            DRP_VeSR1B_y_EngMnSprkNmCrArTqCpFD5_SigSts_Value: accessed-variable=VeSR1B_y_EngMnSprkNmCrArTqCpFD5_SigSts.Value
            DRP_VeSR1B_y_MCPB_MaxTorq_P_FD5_SigSts_Value: accessed-variable=VeSR1B_y_MCPB_MaxTorq_P_FD5_SigSts.Value
            DRP_VeSR1B_y_SGCP_RPM_P_FD5_SigSts_Value: accessed-variable=VeSR1B_y_SGCP_RPM_P_FD5_SigSts.Value
            DRPA_Value_0: accessed-variable=VeSR1B_y_IMPACTCommand_FD3_SigSts.Value
            DRPA_Value_1: accessed-variable=VeSR1B_y_DriverEngineOffRequest_SigSts.Value
        data-send-points:
          50 x access:
            DSP_VeCANR_b_LOC_AGSM_FD16_VeCANR_b_LOC_AGSM_FD16: accessed-variable=VeCANR_b_LOC_AGSM_FD16.VeCANR_b_LOC_AGSM_FD16
            DSP_VeCANR_b_LOC_AGSM_FD3_VeCANR_b_LOC_AGSM_FD3: accessed-variable=VeCANR_b_LOC_AGSM_FD3.VeCANR_b_LOC_AGSM_FD3
            DSP_VeCANR_b_LOC_BCM_FD3_VeCANR_b_LOC_BCM_FD3: accessed-variable=VeCANR_b_LOC_BCM_FD3.VeCANR_b_LOC_BCM_FD3
            DSP_VeCANR_b_LOC_BPCM_FD11_VeCANR_b_LOC_BPCM_FD11: accessed-variable=VeCANR_b_LOC_BPCM_FD11.VeCANR_b_LOC_BPCM_FD11
            DSP_VeCANR_b_LOC_BPCM_FD5_VeCANR_b_LOC_BPCM_FD5: accessed-variable=VeCANR_b_LOC_BPCM_FD5.VeCANR_b_LOC_BPCM_FD5
            DSP_VeCANR_b_LOC_BSM_FD14_VeCANR_b_LOC_BSM_FD14: accessed-variable=VeCANR_b_LOC_BSM_FD14.VeCANR_b_LOC_BSM_FD14
            DSP_VeCANR_b_LOC_CADM_FD14_VeCANR_b_LOC_CADM_FD14: accessed-variable=VeCANR_b_LOC_CADM_FD14.VeCANR_b_LOC_CADM_FD14
            DSP_VeCANR_b_LOC_BSM_FD3_VeCANR_b_LOC_BSM_FD3: accessed-variable=VeCANR_b_LOC_BSM_FD3.VeCANR_b_LOC_BSM_FD3
            DSP_VeCANR_b_LOC_ECM_FD16_VeCANR_b_LOC_ECM_FD16: accessed-variable=VeCANR_b_LOC_ECM_FD16.VeCANR_b_LOC_ECM_FD16
            DSP_VeCANR_b_LOC_ECM_FD3_VeCANR_b_LOC_ECM_FD3: accessed-variable=VeCANR_b_LOC_ECM_FD3.VeCANR_b_LOC_ECM_FD3
            DSP_VeCANR_b_LOC_ECM_FD5_VeCANR_b_LOC_ECM_FD5: accessed-variable=VeCANR_b_LOC_ECM_FD5.VeCANR_b_LOC_ECM_FD5
            DSP_VeCANR_b_LOC_EPS_VeCANR_b_LOC_EPS: accessed-variable=VeCANR_b_LOC_EPS.VeCANR_b_LOC_EPS
            DSP_VeCANR_b_LOC_IDCM_FD11_VeCANR_b_LOC_IDCM_FD11: accessed-variable=VeCANR_b_LOC_IDCM_FD11.VeCANR_b_LOC_IDCM_FD11
            DSP_VeCANR_b_LOC_IDCM_FD5_VeCANR_b_LOC_IDCM_FD5: accessed-variable=VeCANR_b_LOC_IDCM_FD5.VeCANR_b_LOC_IDCM_FD5
            DSP_VeCANR_b_LOC_IPC_FD3_VeCANR_b_LOC_IPC_FD3: accessed-variable=VeCANR_b_LOC_IPC_FD3.VeCANR_b_LOC_IPC_FD3
            DSP_VeCANR_b_LOC_MCPA_FD16_VeCANR_b_LOC_MCPA_FD16: accessed-variable=VeCANR_b_LOC_MCPA_FD16.VeCANR_b_LOC_MCPA_FD16
            DSP_VeCANR_b_LOC_MCPA_FD5_VeCANR_b_LOC_MCPA_FD5: accessed-variable=VeCANR_b_LOC_MCPA_FD5.VeCANR_b_LOC_MCPA_FD5
            DSP_VeCANR_b_LOC_MCPB_FD16_VeCANR_b_LOC_MCPB_FD16: accessed-variable=VeCANR_b_LOC_MCPB_FD16.VeCANR_b_LOC_MCPB_FD16
            DSP_VeCANR_b_LOC_MCPB_FD5_VeCANR_b_LOC_MCPB_FD5: accessed-variable=VeCANR_b_LOC_MCPB_FD5.VeCANR_b_LOC_MCPB_FD5
            DSP_VeCANR_b_LOC_ORC_VeCANR_b_LOC_ORC: accessed-variable=VeCANR_b_LOC_ORC.VeCANR_b_LOC_ORC
            DSP_VeCANR_b_LOC_PPIM_VeCANR_b_LOC_PPIM: accessed-variable=VeCANR_b_LOC_PPIM.VeCANR_b_LOC_PPIM
            DSP_VeCANR_b_LOC_RFHM_VeCANR_b_LOC_RFHM: accessed-variable=VeCANR_b_LOC_RFHM.VeCANR_b_LOC_RFHM
            DSP_VeCANR_b_LOC_SGCP_FD16_VeCANR_b_LOC_SGCP_FD16: accessed-variable=VeCANR_b_LOC_SGCP_FD16.VeCANR_b_LOC_SGCP_FD16
            DSP_VeCANR_b_LOC_SGCP_FD5_VeCANR_b_LOC_SGCP_FD5: accessed-variable=VeCANR_b_LOC_SGCP_FD5.VeCANR_b_LOC_SGCP_FD5
            DSP_VeCANR_b_LOC_SGW_FD11_VeCANR_b_LOC_SGW_FD11: accessed-variable=VeCANR_b_LOC_SGW_FD11.VeCANR_b_LOC_SGW_FD11
            DSP_VeCANR_b_LOC_SGW_FD3_VeCANR_b_LOC_SGW_FD3: accessed-variable=VeCANR_b_LOC_SGW_FD3.VeCANR_b_LOC_SGW_FD3
            DSP_VeCANR_b_LOC_AAD_VeCANR_b_LOC_AAD: accessed-variable=VeCANR_b_LOC_AAD.VeCANR_b_LOC_AAD
            DSP_VeCANR_b_LOC_AGS_VeCANR_b_LOC_AGS: accessed-variable=VeCANR_b_LOC_AGS.VeCANR_b_LOC_AGS
            DSP_VeCANR_b_LOC_AGS2_VeCANR_b_LOC_AGS2: accessed-variable=VeCANR_b_LOC_AGS2.VeCANR_b_LOC_AGS2
            DSP_VeCANR_b_LOC_AHP_VeCANR_b_LOC_AHP: accessed-variable=VeCANR_b_LOC_AHP.VeCANR_b_LOC_AHP
            DSP_VeCANR_b_LOC_BCP_VeCANR_b_LOC_BCP: accessed-variable=VeCANR_b_LOC_BCP.VeCANR_b_LOC_BCP
            DSP_VeCANR_b_LOC_BHV_VeCANR_b_LOC_BHV: accessed-variable=VeCANR_b_LOC_BHV.VeCANR_b_LOC_BHV
            DSP_VeCANR_b_LOC_CEXV_VeCANR_b_LOC_CEXV: accessed-variable=VeCANR_b_LOC_CEXV.VeCANR_b_LOC_CEXV
            DSP_VeCANR_b_LOC_CPIM_VeCANR_b_LOC_CPIM: accessed-variable=VeCANR_b_LOC_CPIM.VeCANR_b_LOC_CPIM
            DSP_VeCANR_b_LOC_CPV_VeCANR_b_LOC_CPV: accessed-variable=VeCANR_b_LOC_CPV.VeCANR_b_LOC_CPV
            DSP_VeCANR_b_LOC_EAC_VeCANR_b_LOC_EAC: accessed-variable=VeCANR_b_LOC_EAC.VeCANR_b_LOC_EAC
            DSP_VeCANR_b_LOC_EAH_VeCANR_b_LOC_EAH: accessed-variable=VeCANR_b_LOC_EAH.VeCANR_b_LOC_EAH
            DSP_VeCANR_b_LOC_ECH_VeCANR_b_LOC_ECH: accessed-variable=VeCANR_b_LOC_ECH.VeCANR_b_LOC_ECH
            DSP_VeCANR_b_LOC_EOPA_VeCANR_b_LOC_EOPA: accessed-variable=VeCANR_b_LOC_EOPA.VeCANR_b_LOC_EOPA
            DSP_VeCANR_b_LOC_EOPB_VeCANR_b_LOC_EOPB: accessed-variable=VeCANR_b_LOC_EOPB.VeCANR_b_LOC_EOPB
            DSP_VeCANR_b_LOC_ESBM_VeCANR_b_LOC_ESBM: accessed-variable=VeCANR_b_LOC_ESBM.VeCANR_b_LOC_ESBM
            DSP_VeCANR_b_LOC_EXV_VeCANR_b_LOC_EXV: accessed-variable=VeCANR_b_LOC_EXV.VeCANR_b_LOC_EXV
            DSP_VeCANR_b_LOC_EXVM_VeCANR_b_LOC_EXVM: accessed-variable=VeCANR_b_LOC_EXVM.VeCANR_b_LOC_EXVM
            DSP_VeCANR_b_LOC_HTLBV_VeCANR_b_LOC_HTLBV: accessed-variable=VeCANR_b_LOC_HTLBV.VeCANR_b_LOC_HTLBV
            DSP_VeCANR_b_LOC_LTRBV_VeCANR_b_LOC_LTRBV: accessed-variable=VeCANR_b_LOC_LTRBV.VeCANR_b_LOC_LTRBV
            DSP_VeCANR_b_LOC_PECP_VeCANR_b_LOC_PECP: accessed-variable=VeCANR_b_LOC_PECP.VeCANR_b_LOC_PECP
            DSP_VeCANR_b_LOC_PECP2_VeCANR_b_LOC_PECP2: accessed-variable=VeCANR_b_LOC_PECP2.VeCANR_b_LOC_PECP2
            DSP_VeCANR_b_LOC_SPP_VeCANR_b_LOC_SPP: accessed-variable=VeCANR_b_LOC_SPP.VeCANR_b_LOC_SPP
            DSP_VeCANR_b_LOC_SPP2_VeCANR_b_LOC_SPP2: accessed-variable=VeCANR_b_LOC_SPP2.VeCANR_b_LOC_SPP2
            DSP_VeCANR_e_CanLocEnblStatus_VeCANR_e_CanLocEnblStatus: accessed-variable=VeCANR_e_CanLocEnblStatus.VeCANR_e_CanLocEnblStatus
        mode-access-point mode-group=MdulPwrMod.AppMode_MDGP_ESH_Mode:
          ident MAP_MdulPwrMod_AppMode_MDGP_ESH_Mode
        mode-access-point mode-group=Pp_DcmControlDTCSetting.MDGP_DcmControlDTCSetting:
          ident MAP_DcmControlDtcSetting_DcmControlDtcSetting
        102 x parameter access:
          SCPVA_KeCANR_t_LOC_EnblCondsMetTi: accessed-parameter=KeCANR_t_LOC_EnblCondsMetTi
          SCPVA_KeCANR_t_LossOfComDiagIniInhbTi: accessed-parameter=KeCANR_t_LOC_DiagIniInhbTi
          SCPVA_KeCAND_g_LOCECU_MdlEnblMask: accessed-parameter=KeCAND_g_LOCECU_MdlEnblMask
          SCPVA_KeCAND_b_U0100_FltEnbl: accessed-parameter=KeCAND_b_U0100_FltEnbl
          SCPVA_KeCAND_b_U0103_FltEnbl: accessed-parameter=KeCAND_b_U0103_FltEnbl
          SCPVA_KeCAND_b_U0110_FltEnbl: accessed-parameter=KeCAND_b_U0110_FltEnbl
          SCPVA_KeCAND_b_U0111_FltEnbl: accessed-parameter=KeCAND_b_U0111_FltEnbl
          SCPVA_KeCAND_b_U0121_FltEnbl: accessed-parameter=KeCAND_b_U0121_FltEnbl
          SCPVA_KeCAND_b_U012D_FltEnbl: accessed-parameter=KeCAND_b_U012D_FltEnbl
          SCPVA_KeCAND_b_U0131_FltEnbl: accessed-parameter=KeCAND_b_U0131_FltEnbl
          SCPVA_KeCAND_b_U0140_FltEnbl: accessed-parameter=KeCAND_b_U0140_FltEnbl
          SCPVA_KeCAND_b_U0149_FltEnbl: accessed-parameter=KeCAND_b_U0149_FltEnbl
          SCPVA_KeCAND_b_U0151_FltEnbl: accessed-parameter=KeCAND_b_U0151_FltEnbl
          SCPVA_KeCAND_b_U0155_FltEnbl: accessed-parameter=KeCAND_b_U0155_FltEnbl
          SCPVA_KeCAND_b_U0292_FltEnbl: accessed-parameter=KeCAND_b_U0292_FltEnbl
          SCPVA_KeCAND_b_U1136_FltEnbl: accessed-parameter=KeCAND_b_U1136_FltEnbl
          SCPVA_KeCAND_b_U1137_FltEnbl: accessed-parameter=KeCAND_b_U1137_FltEnbl
          SCPVA_KeCAND_b_U12AF_FltEnbl: accessed-parameter=KeCAND_b_U12AF_FltEnbl
          SCPVA_KeCAND_b_U12B7_FltEnbl: accessed-parameter=KeCAND_b_U12B7_FltEnbl
          SCPVA_KeCAND_b_U160F_FltEnbl: accessed-parameter=KeCAND_b_U160F_FltEnbl
          SCPVA_KeCAND_b_U{1612..1614}_FltEnbl: accessed-parameter=KeCAND_b_U{1612..1614}_FltEnbl
          SCPVA_KeCAND_b_U1818_FltEnbl: accessed-parameter=KeCAND_b_U1818_FltEnbl
          SCPVA_KeCAND_b_U1831_FltEnbl: accessed-parameter=KeCAND_b_U1831_FltEnbl
          SCPVA_KeCANR_U_LOC_DiagBattVoltMax: accessed-parameter=KeCANR_U_LOC_DiagBattVoltMax
          SCPVA_KeCANR_U_LOC_DiagBattVoltMin: accessed-parameter=KeCANR_U_LOC_DiagBattVoltMin
          CPA_KeCFGR_b_LIN{1..3}_Equid_KeCFGR_b_LIN{1..3}_Equid: accessed-parameter=KeCFGR_b_LIN{1..3}_Equid.KeCFGR_b_LIN{1..3}_Equid
          SCPVA_KeCAND_b_U00C3_FltEnbl: accessed-parameter=KeCAND_b_U00C3_FltEnbl
          SCPVA_KeCAND_b_U00CC_FltEnbl: accessed-parameter=KeCAND_b_U00CC_FltEnbl
          SCPVA_KeCAND_b_U00CD_FltEnbl: accessed-parameter=KeCAND_b_U00CD_FltEnbl
          SCPVA_KeCAND_b_U016B_FltEnbl: accessed-parameter=KeCAND_b_U016B_FltEnbl
          SCPVA_KeCAND_b_U0284_FltEnbl: accessed-parameter=KeCAND_b_U0284_FltEnbl
          SCPVA_KeCAND_b_U0285_FltEnbl: accessed-parameter=KeCAND_b_U0285_FltEnbl
          SCPVA_KeCAND_b_U0623_FltEnbl: accessed-parameter=KeCAND_b_U0623_FltEnbl
          SCPVA_KeCAND_b_U062E_FltEnbl: accessed-parameter=KeCAND_b_U062E_FltEnbl
          SCPVA_KeCAND_b_U{0645..0647}_FltEnbl: accessed-parameter=KeCAND_b_U{0645..0647}_FltEnbl
          SCPVA_KeCAND_b_U0694_FltEnbl: accessed-parameter=KeCAND_b_U0694_FltEnbl
          SCPVA_KeCAND_b_U069E_FltEnbl: accessed-parameter=KeCAND_b_U069E_FltEnbl
          SCPVA_KeCAND_b_U06A0_FltEnbl: accessed-parameter=KeCAND_b_U06A0_FltEnbl
          SCPVA_KeCAND_b_U06A5_FltEnbl: accessed-parameter=KeCAND_b_U06A5_FltEnbl
          SCPVA_KeCAND_b_U112A_FltEnbl: accessed-parameter=KeCAND_b_U112A_FltEnbl
          SCPVA_KeCAND_g_U00C3_GlbEnblMask: accessed-parameter=KeCAND_g_U00C3_GlbEnblMask
          SCPVA_KeCAND_g_U00CC_GlbEnblMask: accessed-parameter=KeCAND_g_U00CC_GlbEnblMask
          SCPVA_KeCAND_g_U00CD_GlbEnblMask: accessed-parameter=KeCAND_g_U00CD_GlbEnblMask
          SCPVA_KeCAND_g_U0100_GlbEnblMask: accessed-parameter=KeCAND_g_U0100_GlbEnblMask
          SCPVA_KeCAND_g_U0103_GlbEnblMask: accessed-parameter=KeCAND_g_U0103_GlbEnblMask
          SCPVA_KeCAND_g_U0110_GlbEnblMask: accessed-parameter=KeCAND_g_U0110_GlbEnblMask
          SCPVA_KeCAND_g_U0111_GlbEnblMask: accessed-parameter=KeCAND_g_U0111_GlbEnblMask
          SCPVA_KeCAND_g_U0121_GlbEnblMask: accessed-parameter=KeCAND_g_U0121_GlbEnblMask
          SCPVA_KeCAND_g_U1815_GlbEnblMask: accessed-parameter=KeCAND_g_U1815_GlbEnblMask
          SCPVA_KeCAND_g_U0131_GlbEnblMask: accessed-parameter=KeCAND_g_U0131_GlbEnblMask
          SCPVA_KeCAND_g_U0140_GlbEnblMask: accessed-parameter=KeCAND_g_U0140_GlbEnblMask
          SCPVA_KeCAND_g_U0149_GlbEnblMask: accessed-parameter=KeCAND_g_U0149_GlbEnblMask
          SCPVA_KeCAND_g_U0151_GlbEnblMask: accessed-parameter=KeCAND_g_U0151_GlbEnblMask
          SCPVA_KeCAND_g_U0155_GlbEnblMask: accessed-parameter=KeCAND_g_U0155_GlbEnblMask
          SCPVA_KeCAND_g_U016B_GlbEnblMask: accessed-parameter=KeCAND_g_U016B_GlbEnblMask
          SCPVA_KeCAND_g_U0284_GlbEnblMask: accessed-parameter=KeCAND_g_U0284_GlbEnblMask
          SCPVA_KeCAND_g_U0285_GlbEnblMask: accessed-parameter=KeCAND_g_U0285_GlbEnblMask
          SCPVA_KeCAND_g_U0292_GlbEnblMask: accessed-parameter=KeCAND_g_U0292_GlbEnblMask
          SCPVA_KeCAND_g_U0623_GlbEnblMask: accessed-parameter=KeCAND_g_U0623_GlbEnblMask
          SCPVA_KeCAND_g_U062E_GlbEnblMask: accessed-parameter=KeCAND_g_U062E_GlbEnblMask
          SCPVA_KeCAND_g_U{0645..0647}_GlbEnblMask: accessed-parameter=KeCAND_g_U{0645..0647}_GlbEnblMask
          SCPVA_KeCAND_g_U0694_GlbEnblMask: accessed-parameter=KeCAND_g_U0694_GlbEnblMask
          SCPVA_KeCAND_g_U069E_GlbEnblMask: accessed-parameter=KeCAND_g_U069E_GlbEnblMask
          SCPVA_KeCAND_g_U06A0_GlbEnblMask: accessed-parameter=KeCAND_g_U06A0_GlbEnblMask
          SCPVA_KeCAND_g_U06A5_GlbEnblMask: accessed-parameter=KeCAND_g_U06A5_GlbEnblMask
          SCPVA_KeCAND_g_U112A_GlbEnblMask: accessed-parameter=KeCAND_g_U112A_GlbEnblMask
          SCPVA_KeCAND_g_U1136_GlbEnblMask: accessed-parameter=KeCAND_g_U1136_GlbEnblMask
          SCPVA_KeCAND_g_U1137_GlbEnblMask: accessed-parameter=KeCAND_g_U1137_GlbEnblMask
          SCPVA_KeCAND_g_U12AF_GlbEnblMask: accessed-parameter=KeCAND_g_U12AF_GlbEnblMask
          SCPVA_KeCAND_g_U12B7_GlbEnblMask: accessed-parameter=KeCAND_g_U12B7_GlbEnblMask
          SCPVA_KeCAND_g_U160F_GlbEnblMask: accessed-parameter=KeCAND_g_U160F_GlbEnblMask
          SCPVA_KeCAND_g_U{1612..1614}_GlbEnblMask: accessed-parameter=KeCAND_g_U{1612..1614}_GlbEnblMask
          SCPVA_KeCAND_g_U1818_GlbEnblMask: accessed-parameter=KeCAND_g_U1818_GlbEnblMask
          SCPVA_KeCAND_g_U1831_GlbEnblMask: accessed-parameter=KeCAND_g_U1831_GlbEnblMask
          CPA_KeCFGR_b_FD14_equid_KeCFGR_b_FD14_equid: accessed-parameter=KeCFGR_b_FD14_equid.KeCFGR_b_FD14_equid
          CPA_KeCFGR_b_FD11_equid_KeCFGR_b_FD11_equid: accessed-parameter=KeCFGR_b_FD11_equid.KeCFGR_b_FD11_equid
          CPA_KeCFGR_b_FD16_equid_KeCFGR_b_FD16_equid: accessed-parameter=KeCFGR_b_FD16_equid.KeCFGR_b_FD16_equid
          CPA_KeCFGR_b_FD3_equid_KeCFGR_b_FD3_equid: accessed-parameter=KeCFGR_b_FD3_equid.KeCFGR_b_FD3_equid
          CPA_KeCFGR_b_FD5_equid_KeCFGR_b_FD5_equid: accessed-parameter=KeCFGR_b_FD5_equid.KeCFGR_b_FD5_equid
          SCPVA_KeCAND_g_U0243_GlbEnblMask: accessed-parameter=KeCAND_g_U0243_GlbEnblMask
          SCPVA_KeCAND_b_U0243_FltEnbl: accessed-parameter=KeCAND_b_U0243_FltEnbl
          SCPVA_KeCAND_g_U015C_GlbEnblMask: accessed-parameter=KeCAND_g_U015C_GlbEnblMask
          SCPVA_KeCAND_b_U015C_FltEnbl: accessed-parameter=KeCAND_b_U015C_FltEnbl
          SCPVA_KeCAND_b_U2007_FltEnbl: accessed-parameter=KeCAND_b_U2007_FltEnbl
          SCPVA_KeCAND_g_U2007_GlbEnblMask: accessed-parameter=KeCAND_g_U2007_GlbEnblMask
          SCPVA_KeCAND_b_U1815_FltEnbl: accessed-parameter=KeCAND_b_U1815_FltEnbl
          SCPVA_KeCAND_b_U1816_FltEnbl: accessed-parameter=KeCAND_b_U1816_FltEnbl
          SCPVA_KeCAND_g_U1816_GlbEnblMask: accessed-parameter=KeCAND_g_U1816_GlbEnblMask
          SCPVA_KeCAND_b_U1615_FltEnbl: accessed-parameter=KeCAND_b_U1615_FltEnbl
          SCPVA_KeCAND_g_U1615_GlbEnblMask: accessed-parameter=KeCAND_g_U1615_GlbEnblMask
          SGVPA_KeCAND_b_U0184_FltEnb: accessed-parameter=KeCAND_b_U0184_FltEnbl
          SCVPA_KeCAND_g_U0184_GlbEnblMask: accessed-parameter=KeCAND_g_U0184_GlbEnblMask
        read-local-variables:
          6 x access:
            IRVRA_VeCAND_Cnt_PrevMode4RstComDiag: accessed-variable=VeCAND_Cnt_PrevMode4RstComDiag
            IRVRA_VeCANR_d_LOC_GlbInhb: accessed-variable=VeCANR_d_LOC_GlbInhb
            IRVRA_VeCANR_g_LOC_Sts: accessed-variable=VeCANR_g_LOC_Sts
            IRVRA_VeCANR_t_LOC_EnblCondsMetTmr: accessed-variable=VeCANR_t_LOC_EnblCondsMetTmr
            IRVRA_VeCANR_t_LOC_IniInhbTmr: accessed-variable=VeCANR_t_LOC_IniInhbTmr
            IRVRA_VeLRNR_d_LIN_LOC_SlaveSts: accessed-variable=VeLRNR_d_LIN_LOC_SlaveSts
        88 x sync call:
          SSCP_EvtInfo_LosCommBECM_A_GetEventStatus: operation=EvtInfo_LosCommBECM_A.GetEventStatus, timeout=0.0
          SSCP_EvtInfo_LosCommBECM_A_CANC11_GetEventStatus: operation=EvtInfo_LosCommBECM_A_CANC11.GetEventStatus, timeout=0.0
          SSCP_EvtInfo_LostCommABSCM_GetEventStatus: operation=EvtInfo_LostCommABSCM.GetEventStatus, timeout=0.0
          SSCP_EvtInfo_LostCommABSCM_A_GetEventStatus: operation=EvtInfo_LostCommABSCM_A.GetEventStatus, timeout=0.0
          SSCP_EvtInfo_LostCommBCM_GetEventStatus: operation=EvtInfo_LostCommBCM.GetEventStatus, timeout=0.0
          SSCP_EvtInfo_LostCommCVPAMod_GetEventStatus: operation=EvtInfo_LostCommCVPAMod.GetEventStatus, timeout=0.0
          SSCP_EvtInfo_LostCommDMCM_2_GetEventStatus: operation=EvtInfo_LostCommDMCM_2.GetEventStatus, timeout=0.0
          SSCP_EvtInfo_LostCommECM_A_BusB_GetEventStatus: operation=EvtInfo_LostCommECM_A_BusB.GetEventStatus, timeout=0.0
          SSCP_EvtInfo_LostCommECM_PCM_A_GetEventStatus: operation=EvtInfo_LostCommECM_PCM_A.GetEventStatus, timeout=0.0
          SSCP_EvtInfo_LostCommESM_BusB_GetEventStatus: operation=EvtInfo_LostCommESM_BusB.GetEventStatus, timeout=0.0
          SSCP_EvtInfo_LostCommElecPwrStrMod_GetEventStatus: operation=EvtInfo_LostCommElecPwrStrMod.GetEventStatus, timeout=0.0
          SSCP_EvtInfo_LostCommIDCM_GetEventStatus: operation=EvtInfo_LostCommIDCM.GetEventStatus, timeout=0.0
          SSCP_EvtInfo_LostCommIPC_GetEventStatus: operation=EvtInfo_LostCommIPC.GetEventStatus, timeout=0.0
          SSCP_EvtInfo_LostCommISM_GetEventStatus: operation=EvtInfo_LostCommISM.GetEventStatus, timeout=0.0
          SSCP_EvtInfo_LostCommORC_GetEventStatus: operation=EvtInfo_LostCommORC.GetEventStatus, timeout=0.0
          SSCP_EvtInfo_LostCommSecurGateway_GetEventStatus: operation=EvtInfo_LostCommSecurGateway.GetEventStatus, timeout=0.0
          SSCP_EvtInfo_LostCommSecurGateway_CAN_GetEventStatus: operation=EvtInfo_LostCommSecurGateway_CAN.GetEventStatus, timeout=0.0
          SSCP_EvtInfo_LostComm_DMCM_A_GetEventStatus: operation=EvtInfo_LostComm_DMCM_A.GetEventStatus, timeout=0.0
          SSCP_EvtInfo_LostComm_DMCM_A_ePT2_GetEventStatus: operation=EvtInfo_LostComm_DMCM_A_ePT2.GetEventStatus, timeout=0.0
          SSCP_EvtInfo_LostComm_DMCM_B_GetEventStatus: operation=EvtInfo_LostComm_DMCM_B.GetEventStatus, timeout=0.0
          SSCP_EvtInfo_LostComm_GenrA_CM_GetEventStatus: operation=EvtInfo_LostComm_GenrA_CM.GetEventStatus, timeout=0.0
          SSCP_EvtInfo_LostComm_GenrA_CM_ePT2_GetEventStatus: operation=EvtInfo_LostComm_GenrA_CM_ePT2.GetEventStatus, timeout=0.0
          SSCP_EvtInfo_LostComm_IDCM_CANC11_GetEventStatus: operation=EvtInfo_LostComm_IDCM_CANC11.GetEventStatus, timeout=0.0
          SSCP_Event_LosCommBECM_A_SetEventStatus: operation=Event_LosCommBECM_A.SetEventStatus, timeout=0.0
          SSCP_Event_LosCommBECM_A_CANC11_SetEventStatus: operation=Event_LosCommBECM_A_CANC11.SetEventStatus, timeout=0.0
          SSCP_Event_LostCommCVPAMod_SetEventStatus: operation=Event_LostCommCVPAMod.SetEventStatus, timeout=0.0
          SSCP_Event_LostCommABSCM_SetEventStatus: operation=Event_LostCommABSCM.SetEventStatus, timeout=0.0
          SSCP_Event_LostCommABSCM_A_SetEventStatus: operation=Event_LostCommABSCM_A.SetEventStatus, timeout=0.0
          SSCP_Event_LostCommBCM_SetEventStatus: operation=Event_LostCommBCM.SetEventStatus, timeout=0.0
          SSCP_Event_LostCommDMCM_2_SetEventStatus: operation=Event_LostCommDMCM_2.SetEventStatus, timeout=0.0
          SSCP_Event_LostCommECM_A_BusB_SetEventStatus: operation=Event_LostCommECM_A_BusB.SetEventStatus, timeout=0.0
          SSCP_Event_LostCommECM_PCM_A_SetEventStatus: operation=Event_LostCommECM_PCM_A.SetEventStatus, timeout=0.0
          SSCP_Event_LostCommESM_BusB_SetEventStatus: operation=Event_LostCommESM_BusB.SetEventStatus, timeout=0.0
          SSCP_Event_LostCommElecPwrStrMod_SetEventStatus: operation=Event_LostCommElecPwrStrMod.SetEventStatus, timeout=0.0
          SSCP_Event_LostCommIDCM_SetEventStatus: operation=Event_LostCommIDCM.SetEventStatus, timeout=0.0
          SSCP_Event_LostCommIPC_SetEventStatus: operation=Event_LostCommIPC.SetEventStatus, timeout=0.0
          SSCP_Event_LostCommISM_SetEventStatus: operation=Event_LostCommISM.SetEventStatus, timeout=0.0
          SSCP_Event_LostCommORC_SetEventStatus: operation=Event_LostCommORC.SetEventStatus, timeout=0.0
          SSCP_Event_LostCommSecurGateway_SetEventStatus: operation=Event_LostCommSecurGateway.SetEventStatus, timeout=0.0
          SSCP_Event_LostCommSecurGateway_CAN_SetEventStatus: operation=Event_LostCommSecurGateway_CAN.SetEventStatus, timeout=0.0
          SSCP_Event_LostComm_DMCM_A_SetEventStatus: operation=Event_LostComm_DMCM_A.SetEventStatus, timeout=0.0
          SSCP_Event_LostComm_DMCM_A_ePT2_SetEventStatus: operation=Event_LostComm_DMCM_A_ePT2.SetEventStatus, timeout=0.0
          SSCP_Event_LostComm_DMCM_B_SetEventStatus: operation=Event_LostComm_DMCM_B.SetEventStatus, timeout=0.0
          SSCP_Event_LostComm_GenrA_CM_SetEventStatus: operation=Event_LostComm_GenrA_CM.SetEventStatus, timeout=0.0
          SSCP_Event_LostComm_GenrA_CM_ePT2_SetEventStatus: operation=Event_LostComm_GenrA_CM_ePT2.SetEventStatus, timeout=0.0
          SSCP_Event_LostComm_IDCM_CANC11_SetEventStatus: operation=Event_LostComm_IDCM_CANC11.SetEventStatus, timeout=0.0
          SSCP_Event_LostComm_AGS_B_SetEventStatus: operation=Event_LostComm_AGS_B.SetEventStatus, timeout=0.0
          SSCP_Event_LostComm_AGS_A_SetEventStatus: operation=Event_LostComm_AGS_A.SetEventStatus, timeout=0.0
          SSCP_Event_LostCommPwrtrn_OilPmp2_SetEventStatus: operation=Event_LostCommPwrtrn_OilPmp2.SetEventStatus, timeout=0.0
          SSCP_Event_LostCommPwrtrn_OilPmp1_SetEventStatus: operation=Event_LostCommPwrtrn_OilPmp1.SetEventStatus, timeout=0.0
          SSCP_Event_LostCommMtrElectCoolPmpB_SetEventStatus: operation=Event_LostCommMtrElectCoolPmpB.SetEventStatus, timeout=0.0
          SSCP_Event_LostCommMtrElectCoolPmpA_SetEventStatus: operation=Event_LostCommMtrElectCoolPmpA.SetEventStatus, timeout=0.0
          SSCP_Event_LostCommHB_CoolPmp_SetEventStatus: operation=Event_LostCommHB_CoolPmp.SetEventStatus, timeout=0.0
          SSCP_Event_LostCommEAC_SetEventStatus: operation=Event_LostCommEAC.SetEventStatus, timeout=0.0
          SSCP_Event_LostCommCoolPmpA_SetEventStatus: operation=Event_LostCommCoolPmpA.SetEventStatus, timeout=0.0
          SSCP_Event_LostCommCoolHtrA_SetEventStatus: operation=Event_LostCommCoolHtrA.SetEventStatus, timeout=0.0
          SSCP_Event_LostCommCPIM_SetEventStatus: operation=Event_LostCommCPIM.SetEventStatus, timeout=0.0
          SSCP_Event_LostCommBHVDummy_SetEventStatus: operation=Event_LostCommBHVDummy.SetEventStatus, timeout=0.0
          SSCP_Event_LostCommActAirDamMod_SetEventStatus: operation=Event_LostCommActAirDamMod.SetEventStatus, timeout=0.0
          SSCP_Event_LostCommACRefrigExpVlvActD_SetEventStatus: operation=Event_LostCommACRefrigExpVlvActD.SetEventStatus, timeout=0.0
          SSCP_Event_LostCommACRefrigExpVlvActC_SetEventStatus: operation=Event_LostCommACRefrigExpVlvActC.SetEventStatus, timeout=0.0
          SSCP_Event_LostCommACRefrigExpVlvActA_SetEventStatus: operation=Event_LostCommACRefrigExpVlvActA.SetEventStatus, timeout=0.0
          SSCP_Event_LosCommHybPSCCtrlValA_SetEventStatus: operation=Event_LosCommHybPSCCtrlValA.SetEventStatus, timeout=0.0
          SSCP_EvtInfo_LosCommHybPSCCtrlValA_GetEventStatus: operation=EvtInfo_LosCommHybPSCCtrlValA.GetEventStatus, timeout=0.0
          SSCP_EvtInfo_LostCommACRefrigExpVlvActA_GetEventStatus: operation=EvtInfo_LostCommACRefrigExpVlvActA.GetEventStatus, timeout=0.0
          SSCP_EvtInfo_LostCommACRefrigExpVlvActC_GetEventStatus: operation=EvtInfo_LostCommACRefrigExpVlvActC.GetEventStatus, timeout=0.0
          SSCP_EvtInfo_LostCommACRefrigExpVlvActD_GetEventStatus: operation=EvtInfo_LostCommACRefrigExpVlvActD.GetEventStatus, timeout=0.0
          SSCP_EvtInfo_LostCommActAirDamMod_GetEventStatus: operation=EvtInfo_LostCommActAirDamMod.GetEventStatus, timeout=0.0
          SSCP_EvtInfo_LostCommCPIM_GetEventStatus: operation=EvtInfo_LostCommCPIM.GetEventStatus, timeout=0.0
          SSCP_EvtInfo_LostCommCoolHtrA_GetEventStatus: operation=EvtInfo_LostCommCoolHtrA.GetEventStatus, timeout=0.0
          SSCP_EvtInfo_LostCommCoolPmpA_GetEventStatus: operation=EvtInfo_LostCommCoolPmpA.GetEventStatus, timeout=0.0
          SSCP_EvtInfo_LostCommEAC_GetEventStatus: operation=EvtInfo_LostCommEAC.GetEventStatus, timeout=0.0
          SSCP_EvtInfo_LostCommHB_CoolPmp_GetEventStatus: operation=EvtInfo_LostCommHB_CoolPmp.GetEventStatus, timeout=0.0
          SSCP_EvtInfo_LostCommMtrElectCoolPmpA_GetEventStatus: operation=EvtInfo_LostCommMtrElectCoolPmpA.GetEventStatus, timeout=0.0
          SSCP_EvtInfo_LostCommMtrElectCoolPmpB_GetEventStatus: operation=EvtInfo_LostCommMtrElectCoolPmpB.GetEventStatus, timeout=0.0
          SSCP_EvtInfo_LostCommPwrtrn_OilPmp1_GetEventStatus: operation=EvtInfo_LostCommPwrtrn_OilPmp1.GetEventStatus, timeout=0.0
          SSCP_EvtInfo_LostCommPwrtrn_OilPmp2_GetEventStatus: operation=EvtInfo_LostCommPwrtrn_OilPmp2.GetEventStatus, timeout=0.0
          SSCP_EvtInfo_LostComm_AGS_A_GetEventStatus: operation=EvtInfo_LostComm_AGS_A.GetEventStatus, timeout=0.0
          SSCP_EvtInfo_LostComm_AGS_B_GetEventStatus: operation=EvtInfo_LostComm_AGS_B.GetEventStatus, timeout=0.0
          SSCP_GetDMRR_g_EnblCondSts_GetDMRR_g_EnblCondSts: operation=GetDMRR_g_EnblCondSts.GetDMRR_g_EnblCondSts, timeout=0.0
          SSCP_EvtInfo_LostCommECM_GetEventStatus: operation=EvtInfo_LostCommECM.GetEventStatus, timeout=0.0
          SSCP_Event_LostCommECM_SetEventStatus: operation=Event_LostCommECM.SetEventStatus, timeout=0.0
          SSCP_EvtInfo_LostComm_DMCM_A_CANC11_GetEventStatus: operation=EvtInfo_LostComm_DMCM_A_CANC11.GetEventStatus
          SSCP_Event_LostComm_DMCM_A_CANC11_SetEventStatus: operation=Event_LostComm_DMCM_A_CANC11.SetEventStatus
          SSCP_Event_LostCommDMCM_2_CANC11_SetEventStatus: operation=Event_LostCommDMCM_2_CANC11.SetEventStatus
          SSCP_EvtInfo_LostCommDMCM_2_CANC11_GetEventStatus: operation=EvtInfo_LostCommDMCM_2_CANC11.GetEventStatus
          SSCP_Event_LostComm_GenrA_CM_ePT_R_SetEventStatus: operation=Event_LostComm_GenrA_CM_ePT_R.SetEventStatus
          SSCP_EvtInfo_LostComm_GenrA_CM_ePT_R_GetEventStatus: operation=EvtInfo_LostComm_GenrA_CM_ePT_R.GetEventStatus
        written-local-variables:
          6 x access:
            IRVWA_VeCAND_Cnt_PrevMode4RstComDiag: accessed-variable=VeCAND_Cnt_PrevMode4RstComDiag
            IRVWA_VeCANR_d_LOC_GlbInhb: accessed-variable=VeCANR_d_LOC_GlbInhb
            IRVWA_VeCANR_g_LOC_Sts: accessed-variable=VeCANR_g_LOC_Sts
            IRVWA_VeCANR_t_LOC_EnblCondsMetTmr: accessed-variable=VeCANR_t_LOC_EnblCondsMetTmr
            IRVWA_VeCANR_t_LOC_IniInhbTmr: accessed-variable=VeCANR_t_LOC_IniInhbTmr
            IRVWA_VeLRNR_d_LIN_LOC_SlaveSts: accessed-variable=VeLRNR_d_LIN_LOC_SlaveSts
      runnable LossOfComCanComDiagInin: symbol=LossOfCanComDiag_LossOfComCanComDiagInin  # Loss Of Communication CAN Communication Diagnosis Initialization
        data-send-points:
          49 x access:
            DSP_VeCANR_b_LOC_AGSM_FD16_VeCANR_b_LOC_AGSM_FD16: accessed-variable=VeCANR_b_LOC_AGSM_FD16.VeCANR_b_LOC_AGSM_FD16
            DSP_VeCANR_b_LOC_AGSM_FD3_VeCANR_b_LOC_AGSM_FD3: accessed-variable=VeCANR_b_LOC_AGSM_FD3.VeCANR_b_LOC_AGSM_FD3
            DSP_VeCANR_b_LOC_BCM_FD3_VeCANR_b_LOC_BCM_FD3: accessed-variable=VeCANR_b_LOC_BCM_FD3.VeCANR_b_LOC_BCM_FD3
            DSP_VeCANR_b_LOC_BPCM_FD11_VeCANR_b_LOC_BPCM_FD11: accessed-variable=VeCANR_b_LOC_BPCM_FD11.VeCANR_b_LOC_BPCM_FD11
            DSP_VeCANR_b_LOC_BPCM_FD5_VeCANR_b_LOC_BPCM_FD5: accessed-variable=VeCANR_b_LOC_BPCM_FD5.VeCANR_b_LOC_BPCM_FD5
            DSP_VeCANR_b_LOC_BSM_FD14_VeCANR_b_LOC_BSM_FD14: accessed-variable=VeCANR_b_LOC_BSM_FD14.VeCANR_b_LOC_BSM_FD14
            DSP_VeCANR_b_LOC_CADM_FD14_VeCANR_b_LOC_CADM_FD14: accessed-variable=VeCANR_b_LOC_CADM_FD14.VeCANR_b_LOC_CADM_FD14
            DSP_VeCANR_b_LOC_BSM_FD3_VeCANR_b_LOC_BSM_FD3: accessed-variable=VeCANR_b_LOC_BSM_FD3.VeCANR_b_LOC_BSM_FD3
            DSP_VeCANR_b_LOC_ECM_FD16_VeCANR_b_LOC_ECM_FD16: accessed-variable=VeCANR_b_LOC_ECM_FD16.VeCANR_b_LOC_ECM_FD16
            DSP_VeCANR_b_LOC_ECM_FD3_VeCANR_b_LOC_ECM_FD3: accessed-variable=VeCANR_b_LOC_ECM_FD3.VeCANR_b_LOC_ECM_FD3
            DSP_VeCANR_b_LOC_ECM_FD5_VeCANR_b_LOC_ECM_FD5: accessed-variable=VeCANR_b_LOC_ECM_FD5.VeCANR_b_LOC_ECM_FD5
            DSP_VeCANR_b_LOC_EPS_VeCANR_b_LOC_EPS: accessed-variable=VeCANR_b_LOC_EPS.VeCANR_b_LOC_EPS
            DSP_VeCANR_b_LOC_IDCM_FD11_VeCANR_b_LOC_IDCM_FD11: accessed-variable=VeCANR_b_LOC_IDCM_FD11.VeCANR_b_LOC_IDCM_FD11
            DSP_VeCANR_b_LOC_IDCM_FD5_VeCANR_b_LOC_IDCM_FD5: accessed-variable=VeCANR_b_LOC_IDCM_FD5.VeCANR_b_LOC_IDCM_FD5
            DSP_VeCANR_b_LOC_IPC_FD3_VeCANR_b_LOC_IPC_FD3: accessed-variable=VeCANR_b_LOC_IPC_FD3.VeCANR_b_LOC_IPC_FD3
            DSP_VeCANR_b_LOC_MCPA_FD16_VeCANR_b_LOC_MCPA_FD16: accessed-variable=VeCANR_b_LOC_MCPA_FD16.VeCANR_b_LOC_MCPA_FD16
            DSP_VeCANR_b_LOC_MCPA_FD5_VeCANR_b_LOC_MCPA_FD5: accessed-variable=VeCANR_b_LOC_MCPA_FD5.VeCANR_b_LOC_MCPA_FD5
            DSP_VeCANR_b_LOC_MCPB_FD16_VeCANR_b_LOC_MCPB_FD16: accessed-variable=VeCANR_b_LOC_MCPB_FD16.VeCANR_b_LOC_MCPB_FD16
            DSP_VeCANR_b_LOC_MCPB_FD5_VeCANR_b_LOC_MCPB_FD5: accessed-variable=VeCANR_b_LOC_MCPB_FD5.VeCANR_b_LOC_MCPB_FD5
            DSP_VeCANR_b_LOC_ORC_VeCANR_b_LOC_ORC: accessed-variable=VeCANR_b_LOC_ORC.VeCANR_b_LOC_ORC
            DSP_VeCANR_b_LOC_PPIM_VeCANR_b_LOC_PPIM: accessed-variable=VeCANR_b_LOC_PPIM.VeCANR_b_LOC_PPIM
            DSP_VeCANR_b_LOC_RFHM_VeCANR_b_LOC_RFHM: accessed-variable=VeCANR_b_LOC_RFHM.VeCANR_b_LOC_RFHM
            DSP_VeCANR_b_LOC_SGCP_FD16_VeCANR_b_LOC_SGCP_FD16: accessed-variable=VeCANR_b_LOC_SGCP_FD16.VeCANR_b_LOC_SGCP_FD16
            DSP_VeCANR_b_LOC_SGCP_FD5_VeCANR_b_LOC_SGCP_FD5: accessed-variable=VeCANR_b_LOC_SGCP_FD5.VeCANR_b_LOC_SGCP_FD5
            DSP_VeCANR_b_LOC_SGW_FD11_VeCANR_b_LOC_SGW_FD11: accessed-variable=VeCANR_b_LOC_SGW_FD11.VeCANR_b_LOC_SGW_FD11
            DSP_VeCANR_b_LOC_SGW_FD3_VeCANR_b_LOC_SGW_FD3: accessed-variable=VeCANR_b_LOC_SGW_FD3.VeCANR_b_LOC_SGW_FD3
            DSP_VeCANR_b_LOC_AAD_VeCANR_b_LOC_AAD: accessed-variable=VeCANR_b_LOC_AAD.VeCANR_b_LOC_AAD
            DSP_VeCANR_b_LOC_AGS_VeCANR_b_LOC_AGS: accessed-variable=VeCANR_b_LOC_AGS.VeCANR_b_LOC_AGS
            DSP_VeCANR_b_LOC_AGS2_VeCANR_b_LOC_AGS2: accessed-variable=VeCANR_b_LOC_AGS2.VeCANR_b_LOC_AGS2
            DSP_VeCANR_b_LOC_AHP_VeCANR_b_LOC_AHP: accessed-variable=VeCANR_b_LOC_AHP.VeCANR_b_LOC_AHP
            DSP_VeCANR_b_LOC_BCP_VeCANR_b_LOC_BCP: accessed-variable=VeCANR_b_LOC_BCP.VeCANR_b_LOC_BCP
            DSP_VeCANR_b_LOC_BHV_VeCANR_b_LOC_BHV: accessed-variable=VeCANR_b_LOC_BHV.VeCANR_b_LOC_BHV
            DSP_VeCANR_b_LOC_CEXV_VeCANR_b_LOC_CEXV: accessed-variable=VeCANR_b_LOC_CEXV.VeCANR_b_LOC_CEXV
            DSP_VeCANR_b_LOC_CPIM_VeCANR_b_LOC_CPIM: accessed-variable=VeCANR_b_LOC_CPIM.VeCANR_b_LOC_CPIM
            DSP_VeCANR_b_LOC_CPV_VeCANR_b_LOC_CPV: accessed-variable=VeCANR_b_LOC_CPV.VeCANR_b_LOC_CPV
            DSP_VeCANR_b_LOC_EAC_VeCANR_b_LOC_EAC: accessed-variable=VeCANR_b_LOC_EAC.VeCANR_b_LOC_EAC
            DSP_VeCANR_b_LOC_EAH_VeCANR_b_LOC_EAH: accessed-variable=VeCANR_b_LOC_EAH.VeCANR_b_LOC_EAH
            DSP_VeCANR_b_LOC_ECH_VeCANR_b_LOC_ECH: accessed-variable=VeCANR_b_LOC_ECH.VeCANR_b_LOC_ECH
            DSP_VeCANR_b_LOC_EOPA_VeCANR_b_LOC_EOPA: accessed-variable=VeCANR_b_LOC_EOPA.VeCANR_b_LOC_EOPA
            DSP_VeCANR_b_LOC_EOPB_VeCANR_b_LOC_EOPB: accessed-variable=VeCANR_b_LOC_EOPB.VeCANR_b_LOC_EOPB
            DSP_VeCANR_b_LOC_ESBM_VeCANR_b_LOC_ESBM: accessed-variable=VeCANR_b_LOC_ESBM.VeCANR_b_LOC_ESBM
            DSP_VeCANR_b_LOC_EXV_VeCANR_b_LOC_EXV: accessed-variable=VeCANR_b_LOC_EXV.VeCANR_b_LOC_EXV
            DSP_VeCANR_b_LOC_EXVM_VeCANR_b_LOC_EXVM: accessed-variable=VeCANR_b_LOC_EXVM.VeCANR_b_LOC_EXVM
            DSP_VeCANR_b_LOC_HTLBV_VeCANR_b_LOC_HTLBV: accessed-variable=VeCANR_b_LOC_HTLBV.VeCANR_b_LOC_HTLBV
            DSP_VeCANR_b_LOC_LTRBV_VeCANR_b_LOC_LTRBV: accessed-variable=VeCANR_b_LOC_LTRBV.VeCANR_b_LOC_LTRBV
            DSP_VeCANR_b_LOC_PECP_VeCANR_b_LOC_PECP: accessed-variable=VeCANR_b_LOC_PECP.VeCANR_b_LOC_PECP
            DSP_VeCANR_b_LOC_PECP2_VeCANR_b_LOC_PECP2: accessed-variable=VeCANR_b_LOC_PECP2.VeCANR_b_LOC_PECP2
            DSP_VeCANR_b_LOC_SPP_VeCANR_b_LOC_SPP: accessed-variable=VeCANR_b_LOC_SPP.VeCANR_b_LOC_SPP
            DSP_VeCANR_b_LOC_SPP2_VeCANR_b_LOC_SPP2: accessed-variable=VeCANR_b_LOC_SPP2.VeCANR_b_LOC_SPP2
        written-local-variables:
          5 x access:
            IRVWA_VeCANR_d_LOC_GlbInhb: accessed-variable=VeCANR_d_LOC_GlbInhb
            IRVWA_VeCANR_g_LOC_Sts: accessed-variable=VeCANR_g_LOC_Sts
            IRVWA_VeCANR_t_LOC_EnblCondsMetTmr: accessed-variable=VeCANR_t_LOC_EnblCondsMetTmr
            IRVWA_VeCANR_t_LOC_IniInhbTmr: accessed-variable=VeCANR_t_LOC_IniInhbTmr
            IRVWA_VeLRNR_d_LIN_LOC_SlaveSts: accessed-variable=VeLRNR_d_LIN_LOC_SlaveSts
      shared-parameters:
        100 x parameter data prototype:
          KeCANR_t_LOC_DiagIniInhbTi: sw-calibration-access=READ-WRITE, type=uint16, init-value=Value:504  # Loss Of Communication Diagnostic Initial Inhibit Time | Time that must elapse before loss of com diagnostics can begin
          KeCANR_t_LOC_EnblCondsMetTi: type=uint16, init-value=Value:504  # Time that the enable conditions must be met for before posting loss of communication faults
          KeCANR_U_LOC_DiagBattVoltMax: sw-calibration-access=READ-WRITE, type=float32, init-value=Value:15.735  # Loss Of Communication Diagnostic Battery Voltage Maximum | Maximum battery voltage allowed for loss of com diagnostics
          KeCAND_g_U0103_GlbEnblMask: type=uint32, init-value=Value:0  # LOC enable condition cal
          KeCAND_g_U0140_GlbEnblMask: type=uint32, init-value=Value:0  # LOC enable condition cal
          KeCAND_g_U0121_GlbEnblMask: type=uint32, init-value=Value:0  # LOC enable condition cal
          KeCAND_g_U0100_GlbEnblMask: type=uint32, init-value=Value:0  # LOC enable condition cal
          KeCAND_g_U0155_GlbEnblMask: type=uint32, init-value=Value:0  # LOC enable condition cal
          KeCAND_g_U0149_GlbEnblMask: type=uint32, init-value=Value:0  # LOC enable condition cal
          KeCAND_g_U1137_GlbEnblMask: type=uint32, init-value=Value:0  # LOC enable condition cal
          KeCAND_g_U160F_GlbEnblMask: type=uint32, init-value=Value:0  # LOC enable condition cal
          KeCAND_g_U{1612..1614}_GlbEnblMask: type=uint32, init-value=Value:0  # LOC enable condition cal
          KeCAND_g_U0111_GlbEnblMask: type=uint32, init-value=Value:0  # LOC enable condition cal
          KeCAND_g_U12AF_GlbEnblMask: type=uint32, init-value=Value:0  # LOC enable condition cal
          KeCAND_g_U1136_GlbEnblMask: type=uint32, init-value=Value:0  # LOC enable condition cal
          KeCAND_g_U12B7_GlbEnblMask: type=uint32, init-value=Value:0  # LOC enable condition cal
          KeCAND_g_U0131_GlbEnblMask: type=uint32, init-value=Value:0  # LOC enable condition cal
          KeCAND_g_U0151_GlbEnblMask: type=uint32, init-value=Value:0  # LOC enable condition cal
          KeCAND_g_U1831_GlbEnblMask: type=uint32, init-value=Value:0  # LOC enable condition cal
          KeCAND_g_U1818_GlbEnblMask: type=uint32, init-value=Value:0  # LOC enable condition cal
          KeCAND_g_U0110_GlbEnblMask: type=uint32, init-value=Value:0  # LOC enable condition cal
          KeCAND_g_U0292_GlbEnblMask: type=uint32, init-value=Value:0  # LOC enable condition cal
          KeCAND_b_U1815_FltEnbl: type=boolean, init-value=Value:0  # LOC enable condition cal
          KeCAND_g_U0645_GlbEnblMask: type=uint32, init-value=Value:0  # LOC enable condition cal
          KeCAND_g_U0694_GlbEnblMask: type=uint32, init-value=Value:0  # LOC enable condition cal
          KeCAND_g_U06A0_GlbEnblMask: type=uint32, init-value=Value:0  # LOC enable condition cal
          KeCAND_g_U069E_GlbEnblMask: type=uint32, init-value=Value:0  # LOC enable condition cal
          KeCAND_g_U062E_GlbEnblMask: type=uint32, init-value=Value:0  # LOC enable condition cal
          KeCAND_g_U00CC_GlbEnblMask: type=uint32, init-value=Value:0  # LOC enable condition cal
          KeCAND_g_U0285_GlbEnblMask: type=uint32, init-value=Value:0  # LOC enable condition cal
          KeCAND_g_U0623_GlbEnblMask: type=uint32, init-value=Value:0  # LOC enable condition cal
          KeCAND_g_U016B_GlbEnblMask: type=uint32, init-value=Value:0  # LOC enable condition cal
          KeCAND_g_U06A5_GlbEnblMask: type=uint32, init-value=Value:0  # LOC enable condition cal
          KeCAND_g_U0646_GlbEnblMask: type=uint32, init-value=Value:0  # LOC enable condition cal
          KeCAND_g_U0284_GlbEnblMask: type=uint32, init-value=Value:0  # LOC enable condition cal
          KeCAND_g_U00C3_GlbEnblMask: type=uint32, init-value=Value:0  # LOC enable condition cal
          KeCAND_g_U112A_GlbEnblMask: type=uint32, init-value=Value:0  # LOC enable condition cal
          KeCAND_g_U00CD_GlbEnblMask: type=uint32, init-value=Value:0  # LOC enable condition cal
          KeCAND_g_U0647_GlbEnblMask: type=uint32, init-value=Value:0  # LOC enable condition cal
          KeCAND_b_U0645_FltEnbl: type=boolean, init-value=Value:1  # This Calibration parameter is used to enable or disable the setting of LOC
          KeCAND_b_U0694_FltEnbl: type=boolean, init-value=Value:1  # This Calibration parameter is used to enable or disable the setting of LOC
          KeCAND_b_U06A0_FltEnbl: type=boolean, init-value=Value:1  # This Calibration parameter is used to enable or disable the setting of LOC
          KeCAND_b_U069E_FltEnbl: type=boolean, init-value=Value:1  # This Calibration parameter is used to enable or disable the setting of LOC
          KeCAND_b_U062E_FltEnbl: type=boolean, init-value=Value:1  # This Calibration parameter is used to enable or disable the setting of LOC
          KeCAND_b_U00CC_FltEnbl: type=boolean, init-value=Value:1  # This Calibration parameter is used to enable or disable the setting of LOC
          KeCAND_b_U0285_FltEnbl: type=boolean, init-value=Value:1  # This Calibration parameter is used to enable or disable the setting of LOC
          KeCAND_b_U0623_FltEnbl: type=boolean, init-value=Value:1  # This Calibration parameter is used to enable or disable the setting of LOC
          KeCAND_b_U016B_FltEnbl: type=boolean, init-value=Value:1  # This Calibration parameter is used to enable or disable the setting of LOC
          KeCAND_b_U06A5_FltEnbl: type=boolean, init-value=Value:1  # This Calibration parameter is used to enable or disable the setting of LOC
          KeCAND_b_U0646_FltEnbl: type=boolean, init-value=Value:1  # This Calibration parameter is used to enable or disable the setting of LOC
          KeCAND_b_U0284_FltEnbl: type=boolean, init-value=Value:1  # This Calibration parameter is used to enable or disable the setting of LOC
          KeCAND_b_U00C3_FltEnbl: type=boolean, init-value=Value:1  # This Calibration parameter is used to enable or disable the setting of LOC
          KeCAND_b_U112A_FltEnbl: type=boolean, init-value=Value:1  # This Calibration parameter is used to enable or disable the setting of LOC
          KeCAND_b_U00CD_FltEnbl: type=boolean, init-value=Value:1  # This Calibration parameter is used to enable or disable the setting of LOC
          KeCAND_b_U0647_FltEnbl: type=boolean, init-value=Value:1  # This Calibration parameter is used to enable or disable the setting of LOC
          KeCAND_b_U012D_FltEnbl: type=boolean, init-value=Value:1  # This Calibration parameter is used to enable or disable the setting of DTC LostComm_GenrA_CM
          KeCAND_b_U0292_FltEnbl: type=boolean, init-value=Value:1  # This Calibration parameter is used to enable or disable the setting of DTC LostCommDMCM_2
          KeCAND_b_U0110_FltEnbl: type=boolean, init-value=Value:1  # This Calibration parameter is used to enable or disable the setting of DTC LostComm_DMCM_A
          KeCAND_b_U1818_FltEnbl: type=boolean, init-value=Value:1  # This Calibration parameter is used to enable or disable the setting of DTC LostCommECM_A_BusB
          KeCAND_b_U1831_FltEnbl: type=boolean, init-value=Value:1  # This Calibration parameter is used to enable or disable the setting of DTC LostCommESM_BusB
          KeCAND_b_U0151_FltEnbl: type=boolean, init-value=Value:1  # This Calibration parameter is used to enable or disable the setting of DTC LostCommORC
          KeCAND_b_U0131_FltEnbl: type=boolean, init-value=Value:1  # This Calibration parameter is used to enable or disable the setting of DTC LostCommElecPwrStrMod
          KeCAND_b_U12B7_FltEnbl: type=boolean, init-value=Value:1  # This Calibration parameter is used to enable or disable the setting of DTC LostCommABSCM_A
          KeCAND_b_U1136_FltEnbl: type=boolean, init-value=Value:1  # This Calibration parameter is used to enable or disable the setting of DTC LostCommSecurGateway_CAN
          KeCAND_b_U12AF_FltEnbl: type=boolean, init-value=Value:1  # This Calibration parameter is used to enable or disable the setting of DTC LostCommIDCM
          KeCAND_b_U0111_FltEnbl: type=boolean, init-value=Value:1  # This Calibration parameter is used to enable or disable the setting of DTC LosCommBECM_A
          KeCAND_b_U1614_FltEnbl: type=boolean, init-value=Value:1  # This Calibration parameter is used to enable or disable the setting of DTC LostComm_GenrA_CM_ePT2
          KeCAND_b_U1613_FltEnbl: type=boolean, init-value=Value:1  # This Calibration parameter is used to enable or disable the setting of DTC LostComm_DMCM_B
          KeCAND_b_U1612_FltEnbl: type=boolean, init-value=Value:1  # This Calibration parameter is used to enable or disable the setting of DTC LostComm_DMCM_A_ePT2
          KeCAND_b_U160F_FltEnbl: type=boolean, init-value=Value:1  # This Calibration parameter is used to enable or disable the setting of DTC LostComm_IDCM_CANC11
          KeCAND_b_U1137_FltEnbl: type=boolean, init-value=Value:1  # This Calibration parameter is used to enable or disable the setting of DTC LosCommBECM_A_CANC11
          KeCAND_b_U0149_FltEnbl: type=boolean, init-value=Value:1  # This Calibration parameter is used to enable or disable the setting of DTC LostCommSecurGateway
          KeCAND_b_U0155_FltEnbl: type=boolean, init-value=Value:1  # This Calibration parameter is used to enable or disable the setting of DTC LostCommIPC
          KeCAND_b_U0100_FltEnbl: type=boolean, init-value=Value:1  # This Calibration parameter is used to enable or disable the setting of DTC LostCommECM_PCM_A
          KeCAND_b_U0121_FltEnbl: type=boolean, init-value=Value:1  # This Calibration parameter is used to enable or disable the setting of DTC LostCommABSCM
          KeCAND_b_U0140_FltEnbl: type=boolean, init-value=Value:1  # This Calibration parameter is used to enable or disable the setting of DTC LostCommBCM
          KeCAND_b_U0103_FltEnbl: type=boolean, init-value=Value:1  # This Calibration parameter is used to enable or disable the setting of DTC LostCommISM
          KeCANR_U_LOC_DiagBattVoltMin: sw-calibration-access=READ-WRITE, type=float32, init-value=Value:10.0  # Loss Of Communication Diagnostic Battery Voltage Minimum | Minimum battery voltage allowed for loss of com diagnostics
          KeCAND_g_LOCECU_MdlEnblMask: type=uint32, init-value=Value:0
          KeCAND_g_U0243_GlbEnblMask: type=uint32, init-value=Value:0
          KeCAND_b_U0243_FltEnbl: type=boolean, init-value=Value:1
          KeCAND_g_U1815_GlbEnblMask: type=uint32, init-value=NumericalValueSpecification_0:0
          KeCAND_b_U1816_FltEnbl: type=boolean, init-value=NumericalValueSpecification_0:1
          KeCAND_g_U1816_GlbEnblMask: type=uint32, init-value=NumericalValueSpecification_0:0
          KeCAND_b_U1615_FltEnbl: sw-impl-policy=FIXED, type=boolean, init-value=NumericalValueSpecification_0:1
          KeCAND_g_U1615_GlbEnblMask: type=uint32, init-value=NumericalValueSpecification_0:0
          KeCAND_b_U2007_FltEnbl: type=boolean, init-value=NumericalValueSpecification_0:1
          KeCAND_g_U2007_GlbEnblMask: type=uint32, init-value=NumericalValueSpecification_0:0
          KeCAND_g_U113A_GlbEnblMask: type=uint32, init-value=NumericalValueSpecification_0:0
          KeCAND_b_U113A_FltEnbl: type=boolean, init-value=NumericalValueSpecification_0:1
          KeCAND_g_U12C2_GlbEnblMask: type=uint32, init-value=NumericalValueSpecification_0:0
          KeCAND_b_U12C2_FltEnbl: type=boolean, init-value=NumericalValueSpecification_0:1
          KeCAND_g_U015C_GlbEnblMask: type=uint32, init-value=NumericalValueSpecification_0:0
          KeCAND_b_U015C_FltEnbl: type=boolean, init-value=NumericalValueSpecification_0:1
          KeCAND_g_U0184_GlbEnblMask: type=uint32, init-value=NumericalValueSpecification_0:0
          KeCAND_b_U0298_FltEnbl: type=boolean, init-value=NumericalValueSpecification_0:1
          KeCAND_b_U0184_FltEnbl: type=boolean, init-value=NumericalValueSpecification_0:1
          KeCAND_g_U0298_GlbEnblMask: type=uint32, init-value=NumericalValueSpecification_0:0
